# sam67_dmpac_wrap0_DMPAC_TOP_CFG_SLV_CP_INTD_CFG_INTD_CFG register map
Vendor: Texas Instruments
Registers are 32-bit, access not given, reset 0x0 unless marked. A register's access mark holds for its fields unless they carry their own. Offsets are as the file gives them; [hi:lo] are bit positions; {n}, {i} and the like mark numbered series.

## sam67_dmpac_wrap0_DMPAC_TOP_CFG_SLV_CP_INTD_CFG_INTD_CFG (part 2 of 2)
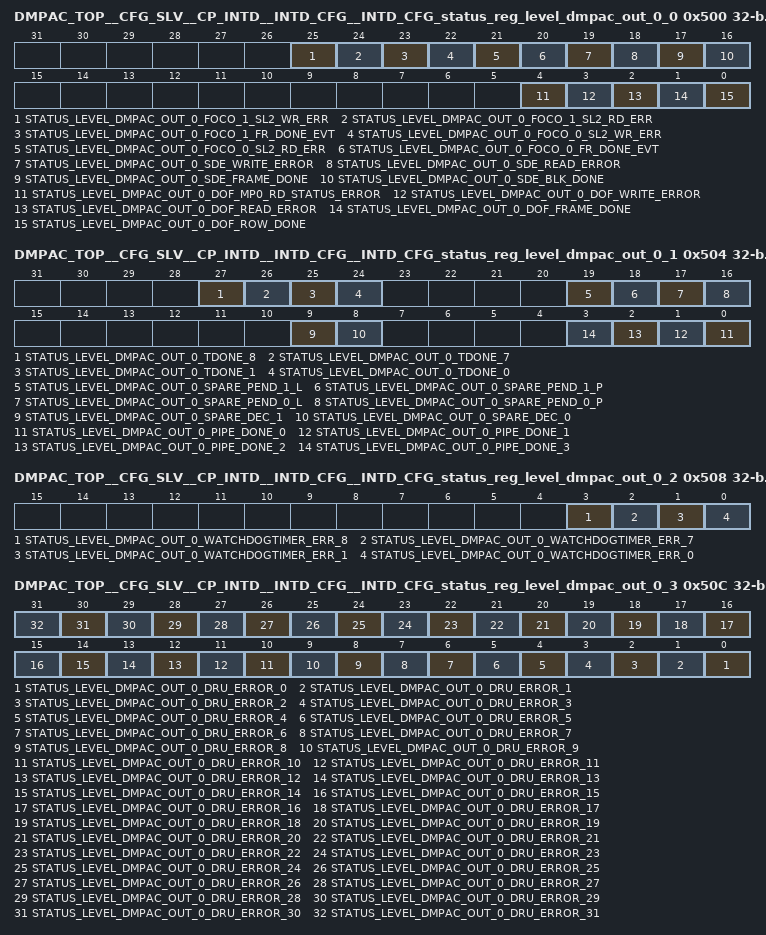
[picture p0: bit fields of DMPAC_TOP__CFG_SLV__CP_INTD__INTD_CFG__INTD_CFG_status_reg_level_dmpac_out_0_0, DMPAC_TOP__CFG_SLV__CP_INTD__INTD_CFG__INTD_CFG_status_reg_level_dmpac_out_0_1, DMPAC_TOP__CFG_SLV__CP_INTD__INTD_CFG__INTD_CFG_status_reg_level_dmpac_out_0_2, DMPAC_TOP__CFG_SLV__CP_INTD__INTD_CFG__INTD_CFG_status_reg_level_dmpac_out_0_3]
0x500 DMPAC_TOP__CFG_SLV__CP_INTD__INTD_CFG__INTD_CFG_status_reg_level_dmpac_out_0_0 — Status Register 0
  [25] STATUS_LEVEL_DMPAC_OUT_0_FOCO_1_SL2_WR_ERR — Status ,write 1 to set, for level_dmpac_out_0_en_foco_1_sl2_wr_err (access R/W1TS)
  [24] STATUS_LEVEL_DMPAC_OUT_0_FOCO_1_SL2_RD_ERR — Status ,write 1 to set, for level_dmpac_out_0_en_foco_1_sl2_rd_err (access R/W1TS)
  [23] STATUS_LEVEL_DMPAC_OUT_0_FOCO_1_FR_DONE_EVT — Status ,write 1 to set, for level_dmpac_out_0_en_foco_1_fr_done_evt (access R/W1TS)
  [22] STATUS_LEVEL_DMPAC_OUT_0_FOCO_0_SL2_WR_ERR — Status ,write 1 to set, for level_dmpac_out_0_en_foco_0_sl2_wr_err (access R/W1TS)
  [21] STATUS_LEVEL_DMPAC_OUT_0_FOCO_0_SL2_RD_ERR — Status ,write 1 to set, for level_dmpac_out_0_en_foco_0_sl2_rd_err (access R/W1TS)
  [20] STATUS_LEVEL_DMPAC_OUT_0_FOCO_0_FR_DONE_EVT — Status ,write 1 to set, for level_dmpac_out_0_en_foco_0_fr_done_evt (access R/W1TS)
  [19] STATUS_LEVEL_DMPAC_OUT_0_SDE_WRITE_ERROR — Status ,write 1 to set, for level_dmpac_out_0_en_sde_write_error (access R/W1TS)
  [18] STATUS_LEVEL_DMPAC_OUT_0_SDE_READ_ERROR — Status ,write 1 to set, for level_dmpac_out_0_en_sde_read_error (access R/W1TS)
  [17] STATUS_LEVEL_DMPAC_OUT_0_SDE_FRAME_DONE — Status ,write 1 to set, for level_dmpac_out_0_en_sde_frame_done (access R/W1TS)
  [16] STATUS_LEVEL_DMPAC_OUT_0_SDE_BLK_DONE — Status ,write 1 to set, for level_dmpac_out_0_en_sde_blk_done (access R/W1TS)
  [4] STATUS_LEVEL_DMPAC_OUT_0_DOF_MP0_RD_STATUS_ERROR — Status ,write 1 to set, for level_dmpac_out_0_en_dof_mp0_rd_status_error (access R/W1TS)
  [3] STATUS_LEVEL_DMPAC_OUT_0_DOF_WRITE_ERROR — Status ,write 1 to set, for level_dmpac_out_0_en_dof_write_error (access R/W1TS)
  [2] STATUS_LEVEL_DMPAC_OUT_0_DOF_READ_ERROR — Status ,write 1 to set, for level_dmpac_out_0_en_dof_read_error (access R/W1TS)
  [1] STATUS_LEVEL_DMPAC_OUT_0_DOF_FRAME_DONE — Status ,write 1 to set, for level_dmpac_out_0_en_dof_frame_done (access R/W1TS)
  [0] STATUS_LEVEL_DMPAC_OUT_0_DOF_ROW_DONE — Status ,write 1 to set, for level_dmpac_out_0_en_dof_row_done (access R/W1TS)
0x504 DMPAC_TOP__CFG_SLV__CP_INTD__INTD_CFG__INTD_CFG_status_reg_level_dmpac_out_0_1 — Status Register 1
  [27] STATUS_LEVEL_DMPAC_OUT_0_TDONE_8 — Status ,write 1 to set, for level_dmpac_out_0_en_tdone_8 (access R/W1TS)
  [26] STATUS_LEVEL_DMPAC_OUT_0_TDONE_7 — Status ,write 1 to set, for level_dmpac_out_0_en_tdone_7 (access R/W1TS)
  [25] STATUS_LEVEL_DMPAC_OUT_0_TDONE_1 — Status ,write 1 to set, for level_dmpac_out_0_en_tdone_1 (access R/W1TS)
  [24] STATUS_LEVEL_DMPAC_OUT_0_TDONE_0 — Status ,write 1 to set, for level_dmpac_out_0_en_tdone_0 (access R/W1TS)
  [19] STATUS_LEVEL_DMPAC_OUT_0_SPARE_PEND_1_L ro — Status for level_dmpac_out_0_en_spare_pend_1_l
  [18] STATUS_LEVEL_DMPAC_OUT_0_SPARE_PEND_1_P ro — Status for level_dmpac_out_0_en_spare_pend_1_p
  [17] STATUS_LEVEL_DMPAC_OUT_0_SPARE_PEND_0_L ro — Status for level_dmpac_out_0_en_spare_pend_0_l
  [16] STATUS_LEVEL_DMPAC_OUT_0_SPARE_PEND_0_P ro — Status for level_dmpac_out_0_en_spare_pend_0_p
  [9] STATUS_LEVEL_DMPAC_OUT_0_SPARE_DEC_1 — Status ,write 1 to set, for level_dmpac_out_0_en_spare_dec_1 (access R/W1TS)
  [8] STATUS_LEVEL_DMPAC_OUT_0_SPARE_DEC_0 — Status ,write 1 to set, for level_dmpac_out_0_en_spare_dec_0 (access R/W1TS)
  [n] STATUS_LEVEL_DMPAC_OUT_0_PIPE_DONE_{n} (n=0..3) — Status ,write 1 to set, for level_dmpac_out_0_en_pipe_done_{n} (access R/W1TS)
0x508 DMPAC_TOP__CFG_SLV__CP_INTD__INTD_CFG__INTD_CFG_status_reg_level_dmpac_out_0_2 — Status Register 2
  [3] STATUS_LEVEL_DMPAC_OUT_0_WATCHDOGTIMER_ERR_8 — Status ,write 1 to set, for level_dmpac_out_0_en_watchdogtimer_err_8 (access R/W1TS)
  [2] STATUS_LEVEL_DMPAC_OUT_0_WATCHDOGTIMER_ERR_7 — Status ,write 1 to set, for level_dmpac_out_0_en_watchdogtimer_err_7 (access R/W1TS)
  [1] STATUS_LEVEL_DMPAC_OUT_0_WATCHDOGTIMER_ERR_1 — Status ,write 1 to set, for level_dmpac_out_0_en_watchdogtimer_err_1 (access R/W1TS)
  [0] STATUS_LEVEL_DMPAC_OUT_0_WATCHDOGTIMER_ERR_0 — Status ,write 1 to set, for level_dmpac_out_0_en_watchdogtimer_err_0 (access R/W1TS)
0x50C DMPAC_TOP__CFG_SLV__CP_INTD__INTD_CFG__INTD_CFG_status_reg_level_dmpac_out_0_3 — Status Register 3
  [n] STATUS_LEVEL_DMPAC_OUT_0_DRU_ERROR_{n} (n=0..31) — Status ,write 1 to set, for level_dmpac_out_0_en_dru_error_{n} (access R/W1TS)
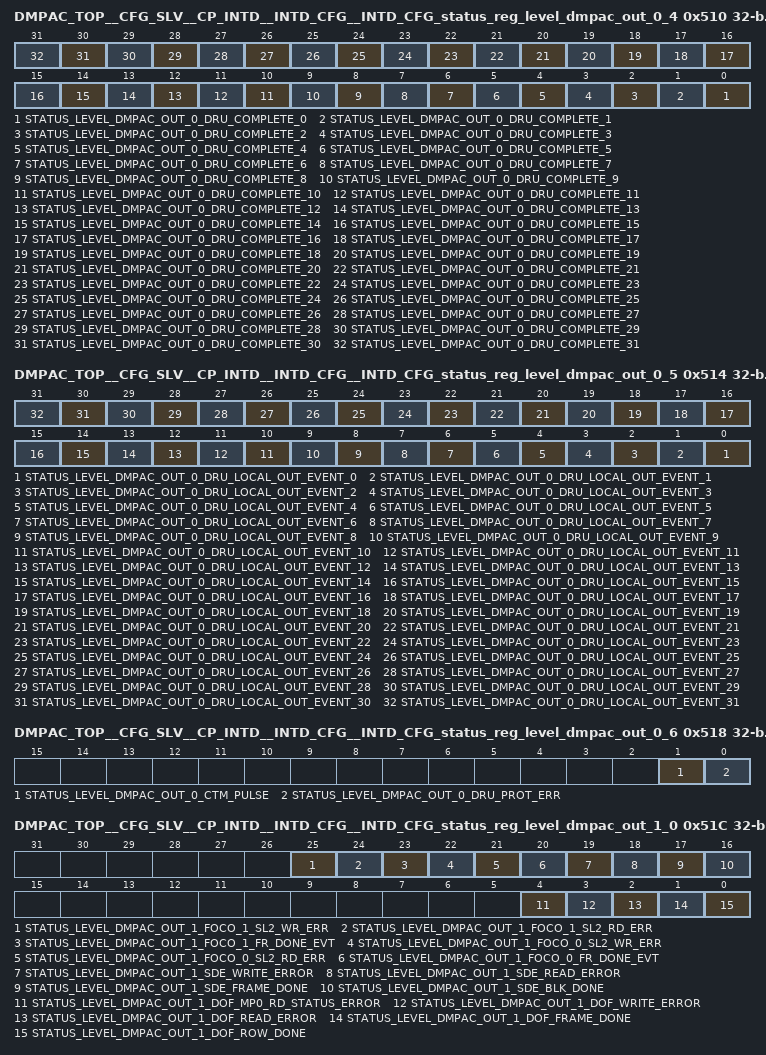
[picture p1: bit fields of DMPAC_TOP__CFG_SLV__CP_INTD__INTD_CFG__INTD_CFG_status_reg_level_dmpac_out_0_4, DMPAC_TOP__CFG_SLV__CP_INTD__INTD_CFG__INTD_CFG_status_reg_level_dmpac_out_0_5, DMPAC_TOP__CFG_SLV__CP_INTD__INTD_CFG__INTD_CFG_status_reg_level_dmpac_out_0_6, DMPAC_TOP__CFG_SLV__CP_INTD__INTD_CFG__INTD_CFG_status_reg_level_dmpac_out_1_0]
0x510 DMPAC_TOP__CFG_SLV__CP_INTD__INTD_CFG__INTD_CFG_status_reg_level_dmpac_out_0_4 — Status Register 4
  [n] STATUS_LEVEL_DMPAC_OUT_0_DRU_COMPLETE_{n} (n=0..31) — Status ,write 1 to set, for level_dmpac_out_0_en_dru_complete_{n} (access R/W1TS)
0x514 DMPAC_TOP__CFG_SLV__CP_INTD__INTD_CFG__INTD_CFG_status_reg_level_dmpac_out_0_5 — Status Register 5
  [n] STATUS_LEVEL_DMPAC_OUT_0_DRU_LOCAL_OUT_EVENT_{n} (n=0..31) — Status ,write 1 to set, for level_dmpac_out_0_en_dru_local_out_event_{n} (access R/W1TS)
0x518 DMPAC_TOP__CFG_SLV__CP_INTD__INTD_CFG__INTD_CFG_status_reg_level_dmpac_out_0_6 — Status Register 6
  [1] STATUS_LEVEL_DMPAC_OUT_0_CTM_PULSE — Status ,write 1 to set, for level_dmpac_out_0_en_ctm_pulse (access R/W1TS)
  [0] STATUS_LEVEL_DMPAC_OUT_0_DRU_PROT_ERR — Status ,write 1 to set, for level_dmpac_out_0_en_dru_prot_err (access R/W1TS)
0x51C DMPAC_TOP__CFG_SLV__CP_INTD__INTD_CFG__INTD_CFG_status_reg_level_dmpac_out_1_0 — Status Register 7
  [25] STATUS_LEVEL_DMPAC_OUT_1_FOCO_1_SL2_WR_ERR — Status ,write 1 to set, for level_dmpac_out_1_en_foco_1_sl2_wr_err (access R/W1TS)
  [24] STATUS_LEVEL_DMPAC_OUT_1_FOCO_1_SL2_RD_ERR — Status ,write 1 to set, for level_dmpac_out_1_en_foco_1_sl2_rd_err (access R/W1TS)
  [23] STATUS_LEVEL_DMPAC_OUT_1_FOCO_1_FR_DONE_EVT — Status ,write 1 to set, for level_dmpac_out_1_en_foco_1_fr_done_evt (access R/W1TS)
  [22] STATUS_LEVEL_DMPAC_OUT_1_FOCO_0_SL2_WR_ERR — Status ,write 1 to set, for level_dmpac_out_1_en_foco_0_sl2_wr_err (access R/W1TS)
  [21] STATUS_LEVEL_DMPAC_OUT_1_FOCO_0_SL2_RD_ERR — Status ,write 1 to set, for level_dmpac_out_1_en_foco_0_sl2_rd_err (access R/W1TS)
  [20] STATUS_LEVEL_DMPAC_OUT_1_FOCO_0_FR_DONE_EVT — Status ,write 1 to set, for level_dmpac_out_1_en_foco_0_fr_done_evt (access R/W1TS)
  [19] STATUS_LEVEL_DMPAC_OUT_1_SDE_WRITE_ERROR — Status ,write 1 to set, for level_dmpac_out_1_en_sde_write_error (access R/W1TS)
  [18] STATUS_LEVEL_DMPAC_OUT_1_SDE_READ_ERROR — Status ,write 1 to set, for level_dmpac_out_1_en_sde_read_error (access R/W1TS)
  [17] STATUS_LEVEL_DMPAC_OUT_1_SDE_FRAME_DONE — Status ,write 1 to set, for level_dmpac_out_1_en_sde_frame_done (access R/W1TS)
  [16] STATUS_LEVEL_DMPAC_OUT_1_SDE_BLK_DONE — Status ,write 1 to set, for level_dmpac_out_1_en_sde_blk_done (access R/W1TS)
  [4] STATUS_LEVEL_DMPAC_OUT_1_DOF_MP0_RD_STATUS_ERROR — Status ,write 1 to set, for level_dmpac_out_1_en_dof_mp0_rd_status_error (access R/W1TS)
  [3] STATUS_LEVEL_DMPAC_OUT_1_DOF_WRITE_ERROR — Status ,write 1 to set, for level_dmpac_out_1_en_dof_write_error (access R/W1TS)
  [2] STATUS_LEVEL_DMPAC_OUT_1_DOF_READ_ERROR — Status ,write 1 to set, for level_dmpac_out_1_en_dof_read_error (access R/W1TS)
  [1] STATUS_LEVEL_DMPAC_OUT_1_DOF_FRAME_DONE — Status ,write 1 to set, for level_dmpac_out_1_en_dof_frame_done (access R/W1TS)
  [0] STATUS_LEVEL_DMPAC_OUT_1_DOF_ROW_DONE — Status ,write 1 to set, for level_dmpac_out_1_en_dof_row_done (access R/W1TS)
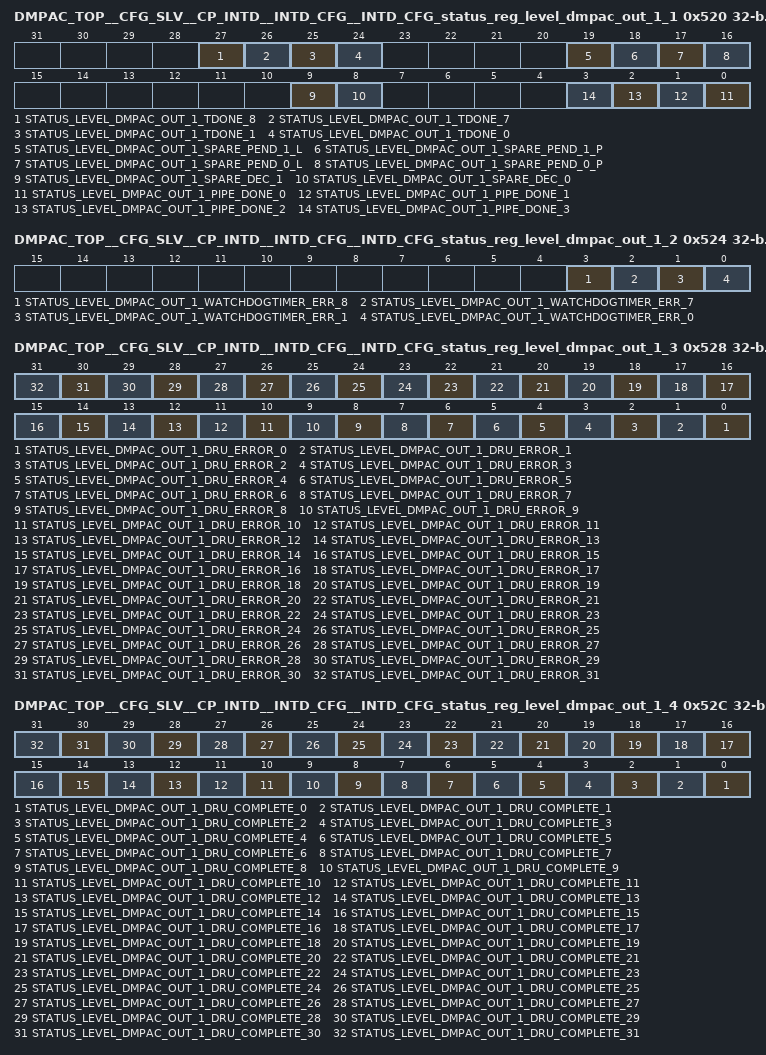
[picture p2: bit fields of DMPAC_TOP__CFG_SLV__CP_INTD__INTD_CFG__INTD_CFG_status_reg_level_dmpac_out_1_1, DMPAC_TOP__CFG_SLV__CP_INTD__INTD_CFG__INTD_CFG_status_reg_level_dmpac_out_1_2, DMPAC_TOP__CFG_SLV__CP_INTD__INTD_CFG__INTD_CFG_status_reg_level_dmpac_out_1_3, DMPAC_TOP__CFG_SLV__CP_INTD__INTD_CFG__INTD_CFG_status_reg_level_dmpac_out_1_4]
0x520 DMPAC_TOP__CFG_SLV__CP_INTD__INTD_CFG__INTD_CFG_status_reg_level_dmpac_out_1_1 — Status Register 8
  [27] STATUS_LEVEL_DMPAC_OUT_1_TDONE_8 — Status ,write 1 to set, for level_dmpac_out_1_en_tdone_8 (access R/W1TS)
  [26] STATUS_LEVEL_DMPAC_OUT_1_TDONE_7 — Status ,write 1 to set, for level_dmpac_out_1_en_tdone_7 (access R/W1TS)
  [25] STATUS_LEVEL_DMPAC_OUT_1_TDONE_1 — Status ,write 1 to set, for level_dmpac_out_1_en_tdone_1 (access R/W1TS)
  [24] STATUS_LEVEL_DMPAC_OUT_1_TDONE_0 — Status ,write 1 to set, for level_dmpac_out_1_en_tdone_0 (access R/W1TS)
  [19] STATUS_LEVEL_DMPAC_OUT_1_SPARE_PEND_1_L ro — Status for level_dmpac_out_1_en_spare_pend_1_l
  [18] STATUS_LEVEL_DMPAC_OUT_1_SPARE_PEND_1_P ro — Status for level_dmpac_out_1_en_spare_pend_1_p
  [17] STATUS_LEVEL_DMPAC_OUT_1_SPARE_PEND_0_L ro — Status for level_dmpac_out_1_en_spare_pend_0_l
  [16] STATUS_LEVEL_DMPAC_OUT_1_SPARE_PEND_0_P ro — Status for level_dmpac_out_1_en_spare_pend_0_p
  [9] STATUS_LEVEL_DMPAC_OUT_1_SPARE_DEC_1 — Status ,write 1 to set, for level_dmpac_out_1_en_spare_dec_1 (access R/W1TS)
  [8] STATUS_LEVEL_DMPAC_OUT_1_SPARE_DEC_0 — Status ,write 1 to set, for level_dmpac_out_1_en_spare_dec_0 (access R/W1TS)
  [n] STATUS_LEVEL_DMPAC_OUT_1_PIPE_DONE_{n} (n=0..3) — Status ,write 1 to set, for level_dmpac_out_1_en_pipe_done_{n} (access R/W1TS)
0x524 DMPAC_TOP__CFG_SLV__CP_INTD__INTD_CFG__INTD_CFG_status_reg_level_dmpac_out_1_2 — Status Register 9
  [3] STATUS_LEVEL_DMPAC_OUT_1_WATCHDOGTIMER_ERR_8 — Status ,write 1 to set, for level_dmpac_out_1_en_watchdogtimer_err_8 (access R/W1TS)
  [2] STATUS_LEVEL_DMPAC_OUT_1_WATCHDOGTIMER_ERR_7 — Status ,write 1 to set, for level_dmpac_out_1_en_watchdogtimer_err_7 (access R/W1TS)
  [1] STATUS_LEVEL_DMPAC_OUT_1_WATCHDOGTIMER_ERR_1 — Status ,write 1 to set, for level_dmpac_out_1_en_watchdogtimer_err_1 (access R/W1TS)
  [0] STATUS_LEVEL_DMPAC_OUT_1_WATCHDOGTIMER_ERR_0 — Status ,write 1 to set, for level_dmpac_out_1_en_watchdogtimer_err_0 (access R/W1TS)
0x528 DMPAC_TOP__CFG_SLV__CP_INTD__INTD_CFG__INTD_CFG_status_reg_level_dmpac_out_1_3 — Status Register 10
  [n] STATUS_LEVEL_DMPAC_OUT_1_DRU_ERROR_{n} (n=0..31) — Status ,write 1 to set, for level_dmpac_out_1_en_dru_error_{n} (access R/W1TS)
0x52C DMPAC_TOP__CFG_SLV__CP_INTD__INTD_CFG__INTD_CFG_status_reg_level_dmpac_out_1_4 — Status Register 11
  [n] STATUS_LEVEL_DMPAC_OUT_1_DRU_COMPLETE_{n} (n=0..31) — Status ,write 1 to set, for level_dmpac_out_1_en_dru_complete_{n} (access R/W1TS)
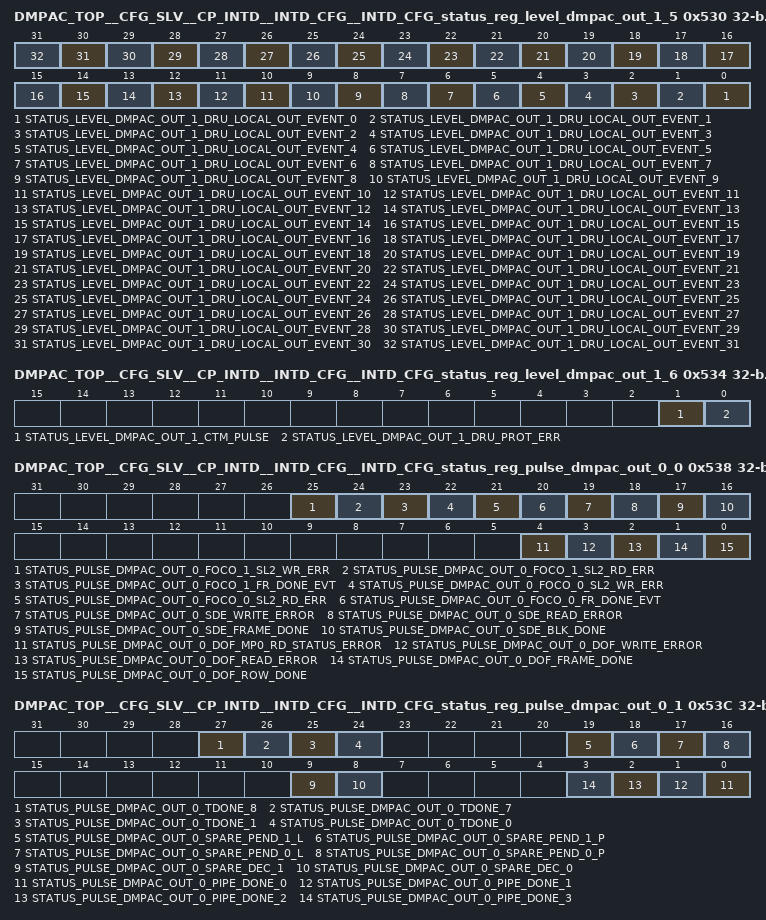
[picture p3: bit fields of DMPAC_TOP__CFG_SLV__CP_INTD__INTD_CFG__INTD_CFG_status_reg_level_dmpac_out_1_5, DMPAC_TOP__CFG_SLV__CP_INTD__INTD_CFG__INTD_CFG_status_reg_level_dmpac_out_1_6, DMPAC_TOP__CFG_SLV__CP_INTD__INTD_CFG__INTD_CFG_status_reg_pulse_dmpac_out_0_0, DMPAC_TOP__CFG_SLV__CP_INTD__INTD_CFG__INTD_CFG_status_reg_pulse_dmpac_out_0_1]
0x530 DMPAC_TOP__CFG_SLV__CP_INTD__INTD_CFG__INTD_CFG_status_reg_level_dmpac_out_1_5 — Status Register 12
  [n] STATUS_LEVEL_DMPAC_OUT_1_DRU_LOCAL_OUT_EVENT_{n} (n=0..31) — Status ,write 1 to set, for level_dmpac_out_1_en_dru_local_out_event_{n} (access R/W1TS)
0x534 DMPAC_TOP__CFG_SLV__CP_INTD__INTD_CFG__INTD_CFG_status_reg_level_dmpac_out_1_6 — Status Register 13
  [1] STATUS_LEVEL_DMPAC_OUT_1_CTM_PULSE — Status ,write 1 to set, for level_dmpac_out_1_en_ctm_pulse (access R/W1TS)
  [0] STATUS_LEVEL_DMPAC_OUT_1_DRU_PROT_ERR — Status ,write 1 to set, for level_dmpac_out_1_en_dru_prot_err (access R/W1TS)
0x538 DMPAC_TOP__CFG_SLV__CP_INTD__INTD_CFG__INTD_CFG_status_reg_pulse_dmpac_out_0_0 — Status Register 14
  [25] STATUS_PULSE_DMPAC_OUT_0_FOCO_1_SL2_WR_ERR — Status ,write 1 to set, for pulse_dmpac_out_0_en_foco_1_sl2_wr_err (access R/W1TS)
  [24] STATUS_PULSE_DMPAC_OUT_0_FOCO_1_SL2_RD_ERR — Status ,write 1 to set, for pulse_dmpac_out_0_en_foco_1_sl2_rd_err (access R/W1TS)
  [23] STATUS_PULSE_DMPAC_OUT_0_FOCO_1_FR_DONE_EVT — Status ,write 1 to set, for pulse_dmpac_out_0_en_foco_1_fr_done_evt (access R/W1TS)
  [22] STATUS_PULSE_DMPAC_OUT_0_FOCO_0_SL2_WR_ERR — Status ,write 1 to set, for pulse_dmpac_out_0_en_foco_0_sl2_wr_err (access R/W1TS)
  [21] STATUS_PULSE_DMPAC_OUT_0_FOCO_0_SL2_RD_ERR — Status ,write 1 to set, for pulse_dmpac_out_0_en_foco_0_sl2_rd_err (access R/W1TS)
  [20] STATUS_PULSE_DMPAC_OUT_0_FOCO_0_FR_DONE_EVT — Status ,write 1 to set, for pulse_dmpac_out_0_en_foco_0_fr_done_evt (access R/W1TS)
  [19] STATUS_PULSE_DMPAC_OUT_0_SDE_WRITE_ERROR — Status ,write 1 to set, for pulse_dmpac_out_0_en_sde_write_error (access R/W1TS)
  [18] STATUS_PULSE_DMPAC_OUT_0_SDE_READ_ERROR — Status ,write 1 to set, for pulse_dmpac_out_0_en_sde_read_error (access R/W1TS)
  [17] STATUS_PULSE_DMPAC_OUT_0_SDE_FRAME_DONE — Status ,write 1 to set, for pulse_dmpac_out_0_en_sde_frame_done (access R/W1TS)
  [16] STATUS_PULSE_DMPAC_OUT_0_SDE_BLK_DONE — Status ,write 1 to set, for pulse_dmpac_out_0_en_sde_blk_done (access R/W1TS)
  [4] STATUS_PULSE_DMPAC_OUT_0_DOF_MP0_RD_STATUS_ERROR — Status ,write 1 to set, for pulse_dmpac_out_0_en_dof_mp0_rd_status_error (access R/W1TS)
  [3] STATUS_PULSE_DMPAC_OUT_0_DOF_WRITE_ERROR — Status ,write 1 to set, for pulse_dmpac_out_0_en_dof_write_error (access R/W1TS)
  [2] STATUS_PULSE_DMPAC_OUT_0_DOF_READ_ERROR — Status ,write 1 to set, for pulse_dmpac_out_0_en_dof_read_error (access R/W1TS)
  [1] STATUS_PULSE_DMPAC_OUT_0_DOF_FRAME_DONE — Status ,write 1 to set, for pulse_dmpac_out_0_en_dof_frame_done (access R/W1TS)
  [0] STATUS_PULSE_DMPAC_OUT_0_DOF_ROW_DONE — Status ,write 1 to set, for pulse_dmpac_out_0_en_dof_row_done (access R/W1TS)
0x53C DMPAC_TOP__CFG_SLV__CP_INTD__INTD_CFG__INTD_CFG_status_reg_pulse_dmpac_out_0_1 — Status Register 15
  [27] STATUS_PULSE_DMPAC_OUT_0_TDONE_8 — Status ,write 1 to set, for pulse_dmpac_out_0_en_tdone_8 (access R/W1TS)
  [26] STATUS_PULSE_DMPAC_OUT_0_TDONE_7 — Status ,write 1 to set, for pulse_dmpac_out_0_en_tdone_7 (access R/W1TS)
  [25] STATUS_PULSE_DMPAC_OUT_0_TDONE_1 — Status ,write 1 to set, for pulse_dmpac_out_0_en_tdone_1 (access R/W1TS)
  [24] STATUS_PULSE_DMPAC_OUT_0_TDONE_0 — Status ,write 1 to set, for pulse_dmpac_out_0_en_tdone_0 (access R/W1TS)
  [19] STATUS_PULSE_DMPAC_OUT_0_SPARE_PEND_1_L ro — Status for pulse_dmpac_out_0_en_spare_pend_1_l
  [18] STATUS_PULSE_DMPAC_OUT_0_SPARE_PEND_1_P ro — Status for pulse_dmpac_out_0_en_spare_pend_1_p
  [17] STATUS_PULSE_DMPAC_OUT_0_SPARE_PEND_0_L ro — Status for pulse_dmpac_out_0_en_spare_pend_0_l
  [16] STATUS_PULSE_DMPAC_OUT_0_SPARE_PEND_0_P ro — Status for pulse_dmpac_out_0_en_spare_pend_0_p
  [9] STATUS_PULSE_DMPAC_OUT_0_SPARE_DEC_1 — Status ,write 1 to set, for pulse_dmpac_out_0_en_spare_dec_1 (access R/W1TS)
  [8] STATUS_PULSE_DMPAC_OUT_0_SPARE_DEC_0 — Status ,write 1 to set, for pulse_dmpac_out_0_en_spare_dec_0 (access R/W1TS)
  [n] STATUS_PULSE_DMPAC_OUT_0_PIPE_DONE_{n} (n=0..3) — Status ,write 1 to set, for pulse_dmpac_out_0_en_pipe_done_{n} (access R/W1TS)
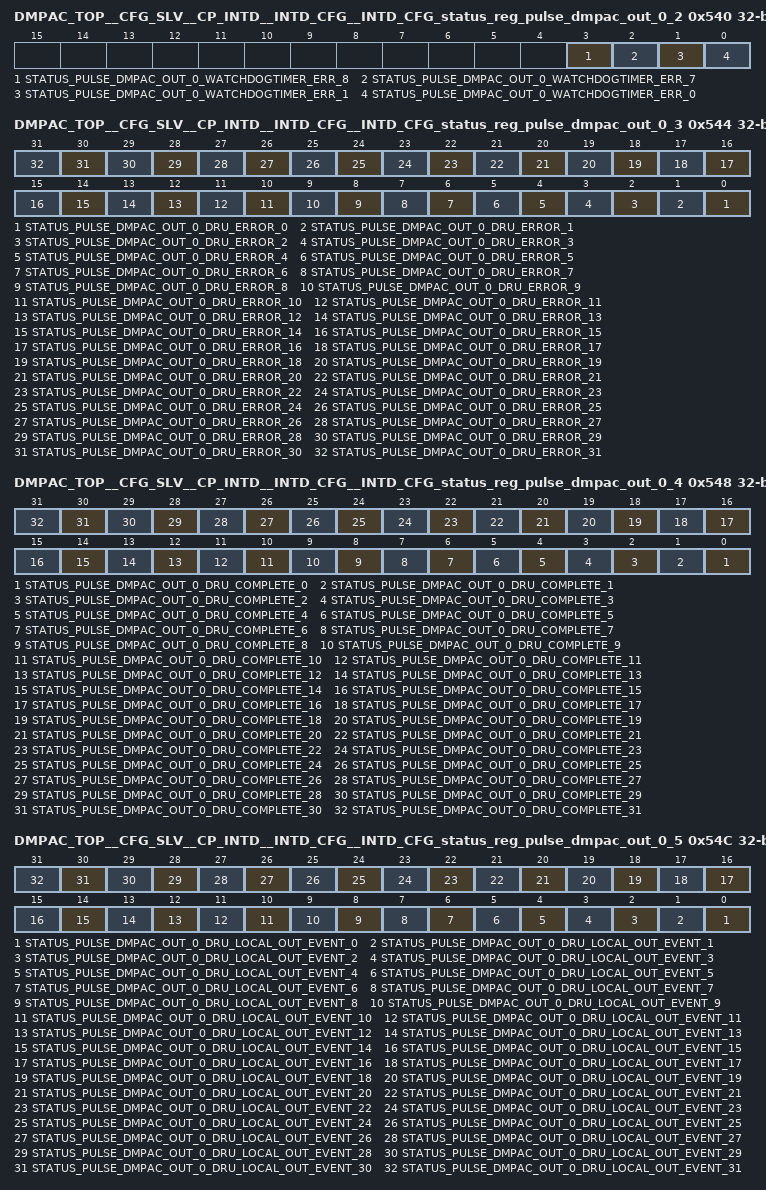
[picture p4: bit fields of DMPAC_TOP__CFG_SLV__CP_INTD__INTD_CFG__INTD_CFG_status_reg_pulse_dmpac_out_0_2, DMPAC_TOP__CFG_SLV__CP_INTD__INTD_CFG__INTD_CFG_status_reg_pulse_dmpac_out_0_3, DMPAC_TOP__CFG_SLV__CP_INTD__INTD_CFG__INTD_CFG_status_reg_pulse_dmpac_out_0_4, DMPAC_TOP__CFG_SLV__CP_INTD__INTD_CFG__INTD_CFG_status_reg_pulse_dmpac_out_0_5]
0x540 DMPAC_TOP__CFG_SLV__CP_INTD__INTD_CFG__INTD_CFG_status_reg_pulse_dmpac_out_0_2 — Status Register 16
  [3] STATUS_PULSE_DMPAC_OUT_0_WATCHDOGTIMER_ERR_8 — Status ,write 1 to set, for pulse_dmpac_out_0_en_watchdogtimer_err_8 (access R/W1TS)
  [2] STATUS_PULSE_DMPAC_OUT_0_WATCHDOGTIMER_ERR_7 — Status ,write 1 to set, for pulse_dmpac_out_0_en_watchdogtimer_err_7 (access R/W1TS)
  [1] STATUS_PULSE_DMPAC_OUT_0_WATCHDOGTIMER_ERR_1 — Status ,write 1 to set, for pulse_dmpac_out_0_en_watchdogtimer_err_1 (access R/W1TS)
  [0] STATUS_PULSE_DMPAC_OUT_0_WATCHDOGTIMER_ERR_0 — Status ,write 1 to set, for pulse_dmpac_out_0_en_watchdogtimer_err_0 (access R/W1TS)
0x544 DMPAC_TOP__CFG_SLV__CP_INTD__INTD_CFG__INTD_CFG_status_reg_pulse_dmpac_out_0_3 — Status Register 17
  [n] STATUS_PULSE_DMPAC_OUT_0_DRU_ERROR_{n} (n=0..31) — Status ,write 1 to set, for pulse_dmpac_out_0_en_dru_error_{n} (access R/W1TS)
0x548 DMPAC_TOP__CFG_SLV__CP_INTD__INTD_CFG__INTD_CFG_status_reg_pulse_dmpac_out_0_4 — Status Register 18
  [n] STATUS_PULSE_DMPAC_OUT_0_DRU_COMPLETE_{n} (n=0..31) — Status ,write 1 to set, for pulse_dmpac_out_0_en_dru_complete_{n} (access R/W1TS)
0x54C DMPAC_TOP__CFG_SLV__CP_INTD__INTD_CFG__INTD_CFG_status_reg_pulse_dmpac_out_0_5 — Status Register 19
  [n] STATUS_PULSE_DMPAC_OUT_0_DRU_LOCAL_OUT_EVENT_{n} (n=0..31) — Status ,write 1 to set, for pulse_dmpac_out_0_en_dru_local_out_event_{n} (access R/W1TS)
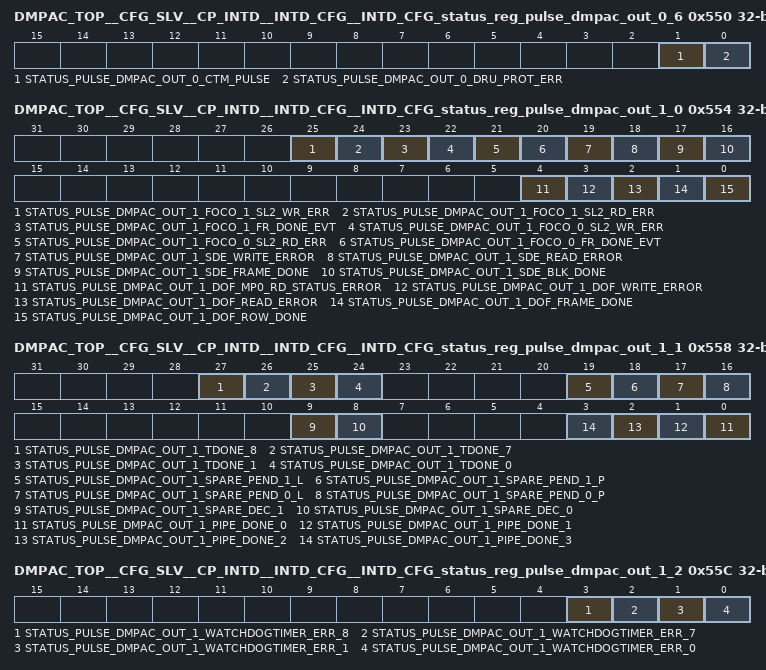
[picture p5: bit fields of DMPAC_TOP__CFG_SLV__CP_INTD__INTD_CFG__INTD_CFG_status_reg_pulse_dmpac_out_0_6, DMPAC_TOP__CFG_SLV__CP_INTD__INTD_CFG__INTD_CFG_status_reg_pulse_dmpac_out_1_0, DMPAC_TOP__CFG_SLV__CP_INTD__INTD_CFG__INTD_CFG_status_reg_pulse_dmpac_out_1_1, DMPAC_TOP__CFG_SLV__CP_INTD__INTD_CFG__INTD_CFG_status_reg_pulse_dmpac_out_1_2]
0x550 DMPAC_TOP__CFG_SLV__CP_INTD__INTD_CFG__INTD_CFG_status_reg_pulse_dmpac_out_0_6 — Status Register 20
  [1] STATUS_PULSE_DMPAC_OUT_0_CTM_PULSE — Status ,write 1 to set, for pulse_dmpac_out_0_en_ctm_pulse (access R/W1TS)
  [0] STATUS_PULSE_DMPAC_OUT_0_DRU_PROT_ERR — Status ,write 1 to set, for pulse_dmpac_out_0_en_dru_prot_err (access R/W1TS)
0x554 DMPAC_TOP__CFG_SLV__CP_INTD__INTD_CFG__INTD_CFG_status_reg_pulse_dmpac_out_1_0 — Status Register 21
  [25] STATUS_PULSE_DMPAC_OUT_1_FOCO_1_SL2_WR_ERR — Status ,write 1 to set, for pulse_dmpac_out_1_en_foco_1_sl2_wr_err (access R/W1TS)
  [24] STATUS_PULSE_DMPAC_OUT_1_FOCO_1_SL2_RD_ERR — Status ,write 1 to set, for pulse_dmpac_out_1_en_foco_1_sl2_rd_err (access R/W1TS)
  [23] STATUS_PULSE_DMPAC_OUT_1_FOCO_1_FR_DONE_EVT — Status ,write 1 to set, for pulse_dmpac_out_1_en_foco_1_fr_done_evt (access R/W1TS)
  [22] STATUS_PULSE_DMPAC_OUT_1_FOCO_0_SL2_WR_ERR — Status ,write 1 to set, for pulse_dmpac_out_1_en_foco_0_sl2_wr_err (access R/W1TS)
  [21] STATUS_PULSE_DMPAC_OUT_1_FOCO_0_SL2_RD_ERR — Status ,write 1 to set, for pulse_dmpac_out_1_en_foco_0_sl2_rd_err (access R/W1TS)
  [20] STATUS_PULSE_DMPAC_OUT_1_FOCO_0_FR_DONE_EVT — Status ,write 1 to set, for pulse_dmpac_out_1_en_foco_0_fr_done_evt (access R/W1TS)
  [19] STATUS_PULSE_DMPAC_OUT_1_SDE_WRITE_ERROR — Status ,write 1 to set, for pulse_dmpac_out_1_en_sde_write_error (access R/W1TS)
  [18] STATUS_PULSE_DMPAC_OUT_1_SDE_READ_ERROR — Status ,write 1 to set, for pulse_dmpac_out_1_en_sde_read_error (access R/W1TS)
  [17] STATUS_PULSE_DMPAC_OUT_1_SDE_FRAME_DONE — Status ,write 1 to set, for pulse_dmpac_out_1_en_sde_frame_done (access R/W1TS)
  [16] STATUS_PULSE_DMPAC_OUT_1_SDE_BLK_DONE — Status ,write 1 to set, for pulse_dmpac_out_1_en_sde_blk_done (access R/W1TS)
  [4] STATUS_PULSE_DMPAC_OUT_1_DOF_MP0_RD_STATUS_ERROR — Status ,write 1 to set, for pulse_dmpac_out_1_en_dof_mp0_rd_status_error (access R/W1TS)
  [3] STATUS_PULSE_DMPAC_OUT_1_DOF_WRITE_ERROR — Status ,write 1 to set, for pulse_dmpac_out_1_en_dof_write_error (access R/W1TS)
  [2] STATUS_PULSE_DMPAC_OUT_1_DOF_READ_ERROR — Status ,write 1 to set, for pulse_dmpac_out_1_en_dof_read_error (access R/W1TS)
  [1] STATUS_PULSE_DMPAC_OUT_1_DOF_FRAME_DONE — Status ,write 1 to set, for pulse_dmpac_out_1_en_dof_frame_done (access R/W1TS)
  [0] STATUS_PULSE_DMPAC_OUT_1_DOF_ROW_DONE — Status ,write 1 to set, for pulse_dmpac_out_1_en_dof_row_done (access R/W1TS)
0x558 DMPAC_TOP__CFG_SLV__CP_INTD__INTD_CFG__INTD_CFG_status_reg_pulse_dmpac_out_1_1 — Status Register 22
  [27] STATUS_PULSE_DMPAC_OUT_1_TDONE_8 — Status ,write 1 to set, for pulse_dmpac_out_1_en_tdone_8 (access R/W1TS)
  [26] STATUS_PULSE_DMPAC_OUT_1_TDONE_7 — Status ,write 1 to set, for pulse_dmpac_out_1_en_tdone_7 (access R/W1TS)
  [25] STATUS_PULSE_DMPAC_OUT_1_TDONE_1 — Status ,write 1 to set, for pulse_dmpac_out_1_en_tdone_1 (access R/W1TS)
  [24] STATUS_PULSE_DMPAC_OUT_1_TDONE_0 — Status ,write 1 to set, for pulse_dmpac_out_1_en_tdone_0 (access R/W1TS)
  [19] STATUS_PULSE_DMPAC_OUT_1_SPARE_PEND_1_L ro — Status for pulse_dmpac_out_1_en_spare_pend_1_l
  [18] STATUS_PULSE_DMPAC_OUT_1_SPARE_PEND_1_P ro — Status for pulse_dmpac_out_1_en_spare_pend_1_p
  [17] STATUS_PULSE_DMPAC_OUT_1_SPARE_PEND_0_L ro — Status for pulse_dmpac_out_1_en_spare_pend_0_l
  [16] STATUS_PULSE_DMPAC_OUT_1_SPARE_PEND_0_P ro — Status for pulse_dmpac_out_1_en_spare_pend_0_p
  [9] STATUS_PULSE_DMPAC_OUT_1_SPARE_DEC_1 — Status ,write 1 to set, for pulse_dmpac_out_1_en_spare_dec_1 (access R/W1TS)
  [8] STATUS_PULSE_DMPAC_OUT_1_SPARE_DEC_0 — Status ,write 1 to set, for pulse_dmpac_out_1_en_spare_dec_0 (access R/W1TS)
  [n] STATUS_PULSE_DMPAC_OUT_1_PIPE_DONE_{n} (n=0..3) — Status ,write 1 to set, for pulse_dmpac_out_1_en_pipe_done_{n} (access R/W1TS)
0x55C DMPAC_TOP__CFG_SLV__CP_INTD__INTD_CFG__INTD_CFG_status_reg_pulse_dmpac_out_1_2 — Status Register 23
  [3] STATUS_PULSE_DMPAC_OUT_1_WATCHDOGTIMER_ERR_8 — Status ,write 1 to set, for pulse_dmpac_out_1_en_watchdogtimer_err_8 (access R/W1TS)
  [2] STATUS_PULSE_DMPAC_OUT_1_WATCHDOGTIMER_ERR_7 — Status ,write 1 to set, for pulse_dmpac_out_1_en_watchdogtimer_err_7 (access R/W1TS)
  [1] STATUS_PULSE_DMPAC_OUT_1_WATCHDOGTIMER_ERR_1 — Status ,write 1 to set, for pulse_dmpac_out_1_en_watchdogtimer_err_1 (access R/W1TS)
  [0] STATUS_PULSE_DMPAC_OUT_1_WATCHDOGTIMER_ERR_0 — Status ,write 1 to set, for pulse_dmpac_out_1_en_watchdogtimer_err_0 (access R/W1TS)
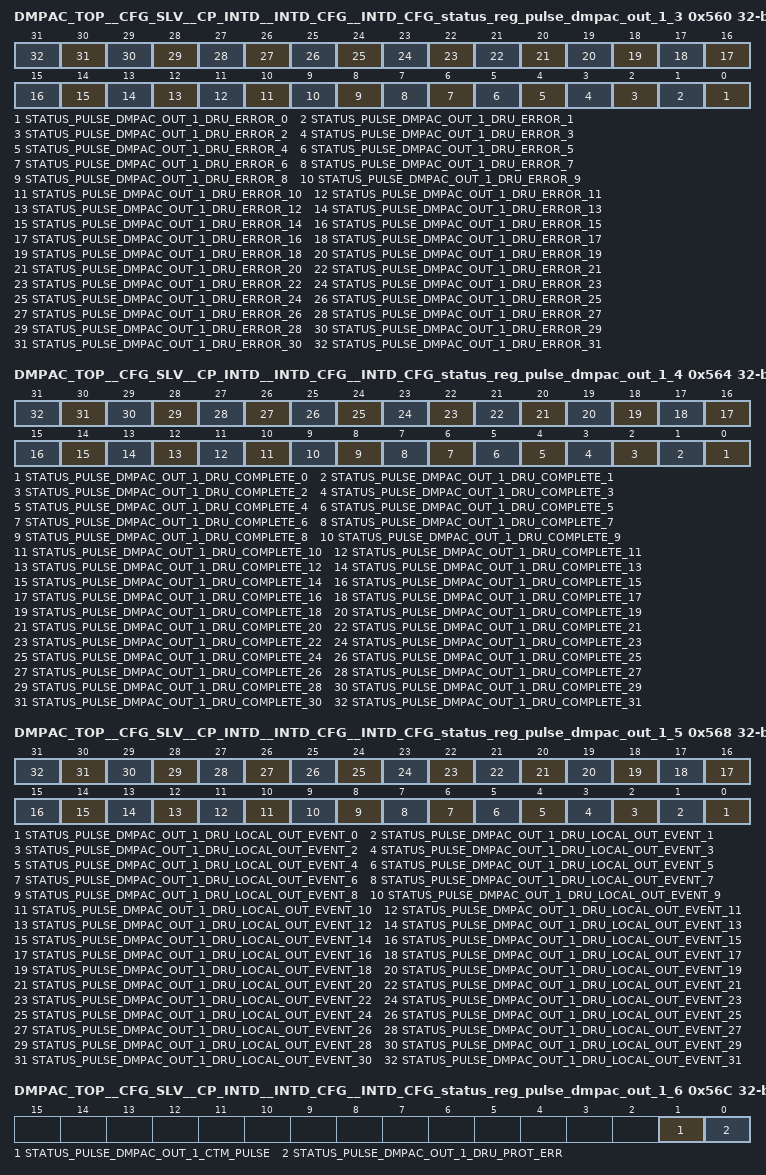
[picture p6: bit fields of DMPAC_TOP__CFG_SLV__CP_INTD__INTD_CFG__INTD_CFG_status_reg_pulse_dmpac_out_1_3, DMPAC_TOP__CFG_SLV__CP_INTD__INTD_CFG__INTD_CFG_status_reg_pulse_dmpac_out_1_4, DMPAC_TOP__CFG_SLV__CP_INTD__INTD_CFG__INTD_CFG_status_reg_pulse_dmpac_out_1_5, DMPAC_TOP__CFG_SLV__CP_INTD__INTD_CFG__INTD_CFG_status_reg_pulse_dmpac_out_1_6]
0x560 DMPAC_TOP__CFG_SLV__CP_INTD__INTD_CFG__INTD_CFG_status_reg_pulse_dmpac_out_1_3 — Status Register 24
  [n] STATUS_PULSE_DMPAC_OUT_1_DRU_ERROR_{n} (n=0..31) — Status ,write 1 to set, for pulse_dmpac_out_1_en_dru_error_{n} (access R/W1TS)
0x564 DMPAC_TOP__CFG_SLV__CP_INTD__INTD_CFG__INTD_CFG_status_reg_pulse_dmpac_out_1_4 — Status Register 25
  [n] STATUS_PULSE_DMPAC_OUT_1_DRU_COMPLETE_{n} (n=0..31) — Status ,write 1 to set, for pulse_dmpac_out_1_en_dru_complete_{n} (access R/W1TS)
0x568 DMPAC_TOP__CFG_SLV__CP_INTD__INTD_CFG__INTD_CFG_status_reg_pulse_dmpac_out_1_5 — Status Register 26
  [n] STATUS_PULSE_DMPAC_OUT_1_DRU_LOCAL_OUT_EVENT_{n} (n=0..31) — Status ,write 1 to set, for pulse_dmpac_out_1_en_dru_local_out_event_{n} (access R/W1TS)
0x56C DMPAC_TOP__CFG_SLV__CP_INTD__INTD_CFG__INTD_CFG_status_reg_pulse_dmpac_out_1_6 — Status Register 27
  [1] STATUS_PULSE_DMPAC_OUT_1_CTM_PULSE — Status ,write 1 to set, for pulse_dmpac_out_1_en_ctm_pulse (access R/W1TS)
  [0] STATUS_PULSE_DMPAC_OUT_1_DRU_PROT_ERR — Status ,write 1 to set, for pulse_dmpac_out_1_en_dru_prot_err (access R/W1TS)
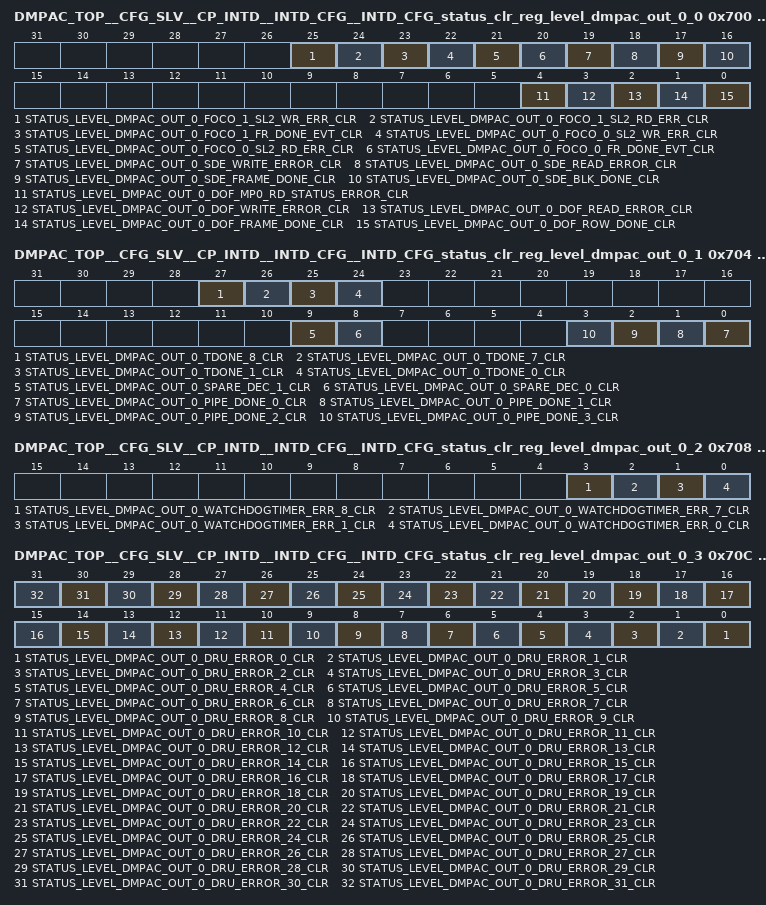
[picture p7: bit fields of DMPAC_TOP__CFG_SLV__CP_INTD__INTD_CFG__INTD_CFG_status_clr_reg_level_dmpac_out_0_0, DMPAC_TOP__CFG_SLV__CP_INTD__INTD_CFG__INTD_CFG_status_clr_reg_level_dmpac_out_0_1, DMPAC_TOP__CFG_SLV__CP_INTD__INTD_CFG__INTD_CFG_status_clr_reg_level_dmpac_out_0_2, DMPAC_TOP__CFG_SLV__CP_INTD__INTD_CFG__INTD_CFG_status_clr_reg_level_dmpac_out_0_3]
0x700 DMPAC_TOP__CFG_SLV__CP_INTD__INTD_CFG__INTD_CFG_status_clr_reg_level_dmpac_out_0_0 — Status Clear Register 0
  [25] STATUS_LEVEL_DMPAC_OUT_0_FOCO_1_SL2_WR_ERR_CLR — Status ,write 1 to clear, for level_dmpac_out_0_en_foco_1_sl2_wr_err (access R/W1TC)
  [24] STATUS_LEVEL_DMPAC_OUT_0_FOCO_1_SL2_RD_ERR_CLR — Status ,write 1 to clear, for level_dmpac_out_0_en_foco_1_sl2_rd_err (access R/W1TC)
  [23] STATUS_LEVEL_DMPAC_OUT_0_FOCO_1_FR_DONE_EVT_CLR — Status ,write 1 to clear, for level_dmpac_out_0_en_foco_1_fr_done_evt (access R/W1TC)
  [22] STATUS_LEVEL_DMPAC_OUT_0_FOCO_0_SL2_WR_ERR_CLR — Status ,write 1 to clear, for level_dmpac_out_0_en_foco_0_sl2_wr_err (access R/W1TC)
  [21] STATUS_LEVEL_DMPAC_OUT_0_FOCO_0_SL2_RD_ERR_CLR — Status ,write 1 to clear, for level_dmpac_out_0_en_foco_0_sl2_rd_err (access R/W1TC)
  [20] STATUS_LEVEL_DMPAC_OUT_0_FOCO_0_FR_DONE_EVT_CLR — Status ,write 1 to clear, for level_dmpac_out_0_en_foco_0_fr_done_evt (access R/W1TC)
  [19] STATUS_LEVEL_DMPAC_OUT_0_SDE_WRITE_ERROR_CLR — Status ,write 1 to clear, for level_dmpac_out_0_en_sde_write_error (access R/W1TC)
  [18] STATUS_LEVEL_DMPAC_OUT_0_SDE_READ_ERROR_CLR — Status ,write 1 to clear, for level_dmpac_out_0_en_sde_read_error (access R/W1TC)
  [17] STATUS_LEVEL_DMPAC_OUT_0_SDE_FRAME_DONE_CLR — Status ,write 1 to clear, for level_dmpac_out_0_en_sde_frame_done (access R/W1TC)
  [16] STATUS_LEVEL_DMPAC_OUT_0_SDE_BLK_DONE_CLR — Status ,write 1 to clear, for level_dmpac_out_0_en_sde_blk_done (access R/W1TC)
  [4] STATUS_LEVEL_DMPAC_OUT_0_DOF_MP0_RD_STATUS_ERROR_CLR — Status ,write 1 to clear, for level_dmpac_out_0_en_dof_mp0_rd_status_error (access R/W1TC)
  [3] STATUS_LEVEL_DMPAC_OUT_0_DOF_WRITE_ERROR_CLR — Status ,write 1 to clear, for level_dmpac_out_0_en_dof_write_error (access R/W1TC)
  [2] STATUS_LEVEL_DMPAC_OUT_0_DOF_READ_ERROR_CLR — Status ,write 1 to clear, for level_dmpac_out_0_en_dof_read_error (access R/W1TC)
  [1] STATUS_LEVEL_DMPAC_OUT_0_DOF_FRAME_DONE_CLR — Status ,write 1 to clear, for level_dmpac_out_0_en_dof_frame_done (access R/W1TC)
  [0] STATUS_LEVEL_DMPAC_OUT_0_DOF_ROW_DONE_CLR — Status ,write 1 to clear, for level_dmpac_out_0_en_dof_row_done (access R/W1TC)
0x704 DMPAC_TOP__CFG_SLV__CP_INTD__INTD_CFG__INTD_CFG_status_clr_reg_level_dmpac_out_0_1 — Status Clear Register 1
  [27] STATUS_LEVEL_DMPAC_OUT_0_TDONE_8_CLR — Status ,write 1 to clear, for level_dmpac_out_0_en_tdone_8 (access R/W1TC)
  [26] STATUS_LEVEL_DMPAC_OUT_0_TDONE_7_CLR — Status ,write 1 to clear, for level_dmpac_out_0_en_tdone_7 (access R/W1TC)
  [25] STATUS_LEVEL_DMPAC_OUT_0_TDONE_1_CLR — Status ,write 1 to clear, for level_dmpac_out_0_en_tdone_1 (access R/W1TC)
  [24] STATUS_LEVEL_DMPAC_OUT_0_TDONE_0_CLR — Status ,write 1 to clear, for level_dmpac_out_0_en_tdone_0 (access R/W1TC)
  [9] STATUS_LEVEL_DMPAC_OUT_0_SPARE_DEC_1_CLR — Status ,write 1 to clear, for level_dmpac_out_0_en_spare_dec_1 (access R/W1TC)
  [8] STATUS_LEVEL_DMPAC_OUT_0_SPARE_DEC_0_CLR — Status ,write 1 to clear, for level_dmpac_out_0_en_spare_dec_0 (access R/W1TC)
  [n] STATUS_LEVEL_DMPAC_OUT_0_PIPE_DONE_{n}_CLR (n=0..3) — Status ,write 1 to clear, for level_dmpac_out_0_en_pipe_done_{n} (access R/W1TC)
0x708 DMPAC_TOP__CFG_SLV__CP_INTD__INTD_CFG__INTD_CFG_status_clr_reg_level_dmpac_out_0_2 — Status Clear Register 2
  [3] STATUS_LEVEL_DMPAC_OUT_0_WATCHDOGTIMER_ERR_8_CLR — Status ,write 1 to clear, for level_dmpac_out_0_en_watchdogtimer_err_8 (access R/W1TC)
  [2] STATUS_LEVEL_DMPAC_OUT_0_WATCHDOGTIMER_ERR_7_CLR — Status ,write 1 to clear, for level_dmpac_out_0_en_watchdogtimer_err_7 (access R/W1TC)
  [1] STATUS_LEVEL_DMPAC_OUT_0_WATCHDOGTIMER_ERR_1_CLR — Status ,write 1 to clear, for level_dmpac_out_0_en_watchdogtimer_err_1 (access R/W1TC)
  [0] STATUS_LEVEL_DMPAC_OUT_0_WATCHDOGTIMER_ERR_0_CLR — Status ,write 1 to clear, for level_dmpac_out_0_en_watchdogtimer_err_0 (access R/W1TC)
0x70C DMPAC_TOP__CFG_SLV__CP_INTD__INTD_CFG__INTD_CFG_status_clr_reg_level_dmpac_out_0_3 — Status Clear Register 3
  [n] STATUS_LEVEL_DMPAC_OUT_0_DRU_ERROR_{n}_CLR (n=0..31) — Status ,write 1 to clear, for level_dmpac_out_0_en_dru_error_{n} (access R/W1TC)
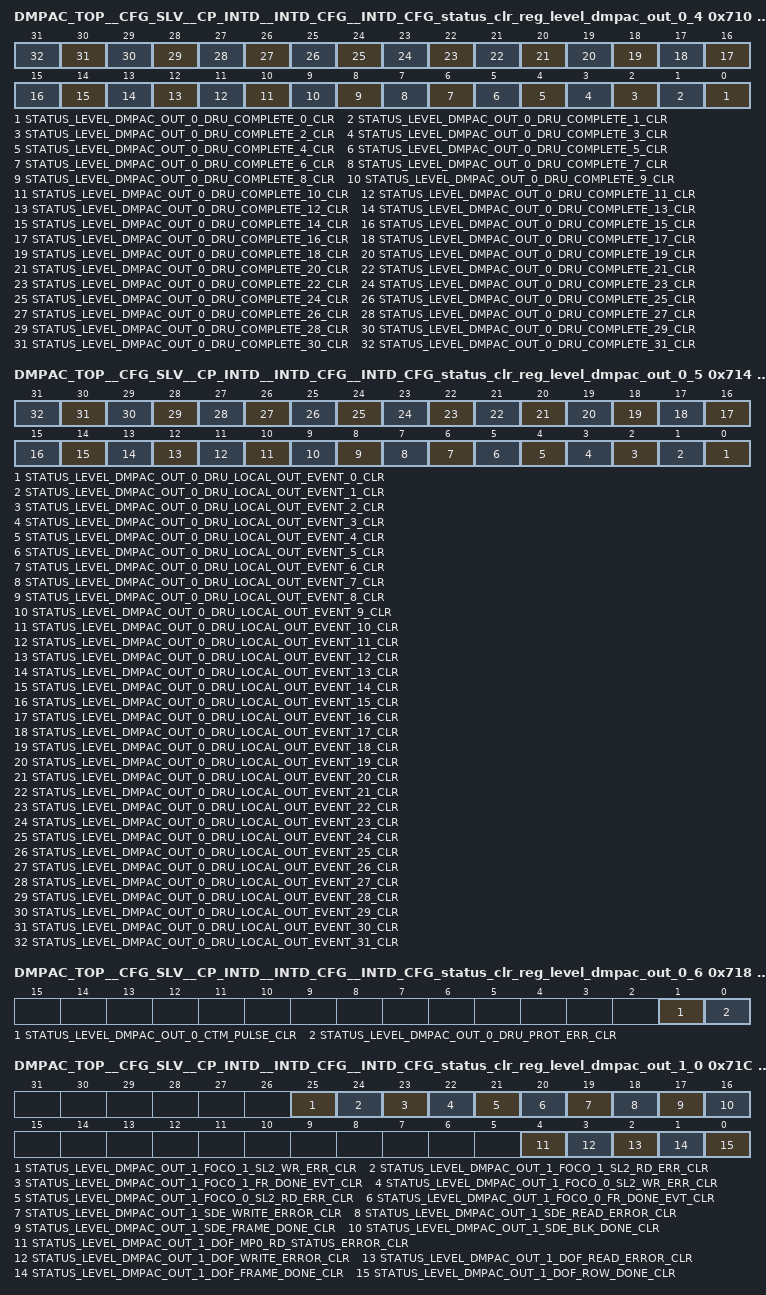
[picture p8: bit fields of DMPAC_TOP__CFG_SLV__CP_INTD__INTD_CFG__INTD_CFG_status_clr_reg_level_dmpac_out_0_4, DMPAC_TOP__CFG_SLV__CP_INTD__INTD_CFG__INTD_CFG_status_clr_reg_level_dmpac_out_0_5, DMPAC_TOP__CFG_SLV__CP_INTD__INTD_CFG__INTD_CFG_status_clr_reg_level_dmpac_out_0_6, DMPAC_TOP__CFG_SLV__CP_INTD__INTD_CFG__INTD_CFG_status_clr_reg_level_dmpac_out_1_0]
0x710 DMPAC_TOP__CFG_SLV__CP_INTD__INTD_CFG__INTD_CFG_status_clr_reg_level_dmpac_out_0_4 — Status Clear Register 4
  [n] STATUS_LEVEL_DMPAC_OUT_0_DRU_COMPLETE_{n}_CLR (n=0..31) — Status ,write 1 to clear, for level_dmpac_out_0_en_dru_complete_{n} (access R/W1TC)
0x714 DMPAC_TOP__CFG_SLV__CP_INTD__INTD_CFG__INTD_CFG_status_clr_reg_level_dmpac_out_0_5 — Status Clear Register 5
  [n] STATUS_LEVEL_DMPAC_OUT_0_DRU_LOCAL_OUT_EVENT_{n}_CLR (n=0..31) — Status ,write 1 to clear, for level_dmpac_out_0_en_dru_local_out_event_{n} (access R/W1TC)
0x718 DMPAC_TOP__CFG_SLV__CP_INTD__INTD_CFG__INTD_CFG_status_clr_reg_level_dmpac_out_0_6 — Status Clear Register 6
  [1] STATUS_LEVEL_DMPAC_OUT_0_CTM_PULSE_CLR — Status ,write 1 to clear, for level_dmpac_out_0_en_ctm_pulse (access R/W1TC)
  [0] STATUS_LEVEL_DMPAC_OUT_0_DRU_PROT_ERR_CLR — Status ,write 1 to clear, for level_dmpac_out_0_en_dru_prot_err (access R/W1TC)
0x71C DMPAC_TOP__CFG_SLV__CP_INTD__INTD_CFG__INTD_CFG_status_clr_reg_level_dmpac_out_1_0 — Status Clear Register 7
  [25] STATUS_LEVEL_DMPAC_OUT_1_FOCO_1_SL2_WR_ERR_CLR — Status ,write 1 to clear, for level_dmpac_out_1_en_foco_1_sl2_wr_err (access R/W1TC)
  [24] STATUS_LEVEL_DMPAC_OUT_1_FOCO_1_SL2_RD_ERR_CLR — Status ,write 1 to clear, for level_dmpac_out_1_en_foco_1_sl2_rd_err (access R/W1TC)
  [23] STATUS_LEVEL_DMPAC_OUT_1_FOCO_1_FR_DONE_EVT_CLR — Status ,write 1 to clear, for level_dmpac_out_1_en_foco_1_fr_done_evt (access R/W1TC)
  [22] STATUS_LEVEL_DMPAC_OUT_1_FOCO_0_SL2_WR_ERR_CLR — Status ,write 1 to clear, for level_dmpac_out_1_en_foco_0_sl2_wr_err (access R/W1TC)
  [21] STATUS_LEVEL_DMPAC_OUT_1_FOCO_0_SL2_RD_ERR_CLR — Status ,write 1 to clear, for level_dmpac_out_1_en_foco_0_sl2_rd_err (access R/W1TC)
  [20] STATUS_LEVEL_DMPAC_OUT_1_FOCO_0_FR_DONE_EVT_CLR — Status ,write 1 to clear, for level_dmpac_out_1_en_foco_0_fr_done_evt (access R/W1TC)
  [19] STATUS_LEVEL_DMPAC_OUT_1_SDE_WRITE_ERROR_CLR — Status ,write 1 to clear, for level_dmpac_out_1_en_sde_write_error (access R/W1TC)
  [18] STATUS_LEVEL_DMPAC_OUT_1_SDE_READ_ERROR_CLR — Status ,write 1 to clear, for level_dmpac_out_1_en_sde_read_error (access R/W1TC)
  [17] STATUS_LEVEL_DMPAC_OUT_1_SDE_FRAME_DONE_CLR — Status ,write 1 to clear, for level_dmpac_out_1_en_sde_frame_done (access R/W1TC)
  [16] STATUS_LEVEL_DMPAC_OUT_1_SDE_BLK_DONE_CLR — Status ,write 1 to clear, for level_dmpac_out_1_en_sde_blk_done (access R/W1TC)
  [4] STATUS_LEVEL_DMPAC_OUT_1_DOF_MP0_RD_STATUS_ERROR_CLR — Status ,write 1 to clear, for level_dmpac_out_1_en_dof_mp0_rd_status_error (access R/W1TC)
  [3] STATUS_LEVEL_DMPAC_OUT_1_DOF_WRITE_ERROR_CLR — Status ,write 1 to clear, for level_dmpac_out_1_en_dof_write_error (access R/W1TC)
  [2] STATUS_LEVEL_DMPAC_OUT_1_DOF_READ_ERROR_CLR — Status ,write 1 to clear, for level_dmpac_out_1_en_dof_read_error (access R/W1TC)
  [1] STATUS_LEVEL_DMPAC_OUT_1_DOF_FRAME_DONE_CLR — Status ,write 1 to clear, for level_dmpac_out_1_en_dof_frame_done (access R/W1TC)
  [0] STATUS_LEVEL_DMPAC_OUT_1_DOF_ROW_DONE_CLR — Status ,write 1 to clear, for level_dmpac_out_1_en_dof_row_done (access R/W1TC)
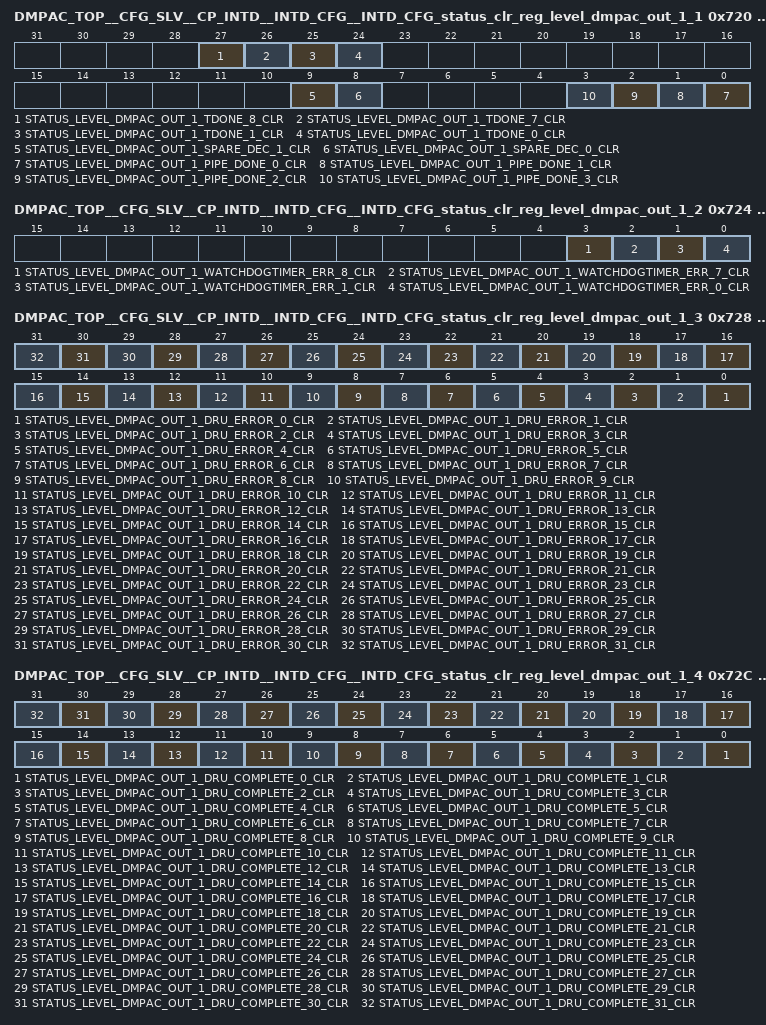
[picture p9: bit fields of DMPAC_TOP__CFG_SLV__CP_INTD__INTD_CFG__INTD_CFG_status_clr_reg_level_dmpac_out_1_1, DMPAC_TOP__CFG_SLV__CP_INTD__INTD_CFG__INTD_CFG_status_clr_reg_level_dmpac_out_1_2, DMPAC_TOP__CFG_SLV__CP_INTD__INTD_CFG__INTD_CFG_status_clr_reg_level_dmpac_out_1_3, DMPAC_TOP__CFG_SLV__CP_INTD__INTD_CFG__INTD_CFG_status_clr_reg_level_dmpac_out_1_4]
0x720 DMPAC_TOP__CFG_SLV__CP_INTD__INTD_CFG__INTD_CFG_status_clr_reg_level_dmpac_out_1_1 — Status Clear Register 8
  [27] STATUS_LEVEL_DMPAC_OUT_1_TDONE_8_CLR — Status ,write 1 to clear, for level_dmpac_out_1_en_tdone_8 (access R/W1TC)
  [26] STATUS_LEVEL_DMPAC_OUT_1_TDONE_7_CLR — Status ,write 1 to clear, for level_dmpac_out_1_en_tdone_7 (access R/W1TC)
  [25] STATUS_LEVEL_DMPAC_OUT_1_TDONE_1_CLR — Status ,write 1 to clear, for level_dmpac_out_1_en_tdone_1 (access R/W1TC)
  [24] STATUS_LEVEL_DMPAC_OUT_1_TDONE_0_CLR — Status ,write 1 to clear, for level_dmpac_out_1_en_tdone_0 (access R/W1TC)
  [9] STATUS_LEVEL_DMPAC_OUT_1_SPARE_DEC_1_CLR — Status ,write 1 to clear, for level_dmpac_out_1_en_spare_dec_1 (access R/W1TC)
  [8] STATUS_LEVEL_DMPAC_OUT_1_SPARE_DEC_0_CLR — Status ,write 1 to clear, for level_dmpac_out_1_en_spare_dec_0 (access R/W1TC)
  [n] STATUS_LEVEL_DMPAC_OUT_1_PIPE_DONE_{n}_CLR (n=0..3) — Status ,write 1 to clear, for level_dmpac_out_1_en_pipe_done_{n} (access R/W1TC)
0x724 DMPAC_TOP__CFG_SLV__CP_INTD__INTD_CFG__INTD_CFG_status_clr_reg_level_dmpac_out_1_2 — Status Clear Register 9
  [3] STATUS_LEVEL_DMPAC_OUT_1_WATCHDOGTIMER_ERR_8_CLR — Status ,write 1 to clear, for level_dmpac_out_1_en_watchdogtimer_err_8 (access R/W1TC)
  [2] STATUS_LEVEL_DMPAC_OUT_1_WATCHDOGTIMER_ERR_7_CLR — Status ,write 1 to clear, for level_dmpac_out_1_en_watchdogtimer_err_7 (access R/W1TC)
  [1] STATUS_LEVEL_DMPAC_OUT_1_WATCHDOGTIMER_ERR_1_CLR — Status ,write 1 to clear, for level_dmpac_out_1_en_watchdogtimer_err_1 (access R/W1TC)
  [0] STATUS_LEVEL_DMPAC_OUT_1_WATCHDOGTIMER_ERR_0_CLR — Status ,write 1 to clear, for level_dmpac_out_1_en_watchdogtimer_err_0 (access R/W1TC)
0x728 DMPAC_TOP__CFG_SLV__CP_INTD__INTD_CFG__INTD_CFG_status_clr_reg_level_dmpac_out_1_3 — Status Clear Register 10
  [n] STATUS_LEVEL_DMPAC_OUT_1_DRU_ERROR_{n}_CLR (n=0..31) — Status ,write 1 to clear, for level_dmpac_out_1_en_dru_error_{n} (access R/W1TC)
0x72C DMPAC_TOP__CFG_SLV__CP_INTD__INTD_CFG__INTD_CFG_status_clr_reg_level_dmpac_out_1_4 — Status Clear Register 11
  [n] STATUS_LEVEL_DMPAC_OUT_1_DRU_COMPLETE_{n}_CLR (n=0..31) — Status ,write 1 to clear, for level_dmpac_out_1_en_dru_complete_{n} (access R/W1TC)
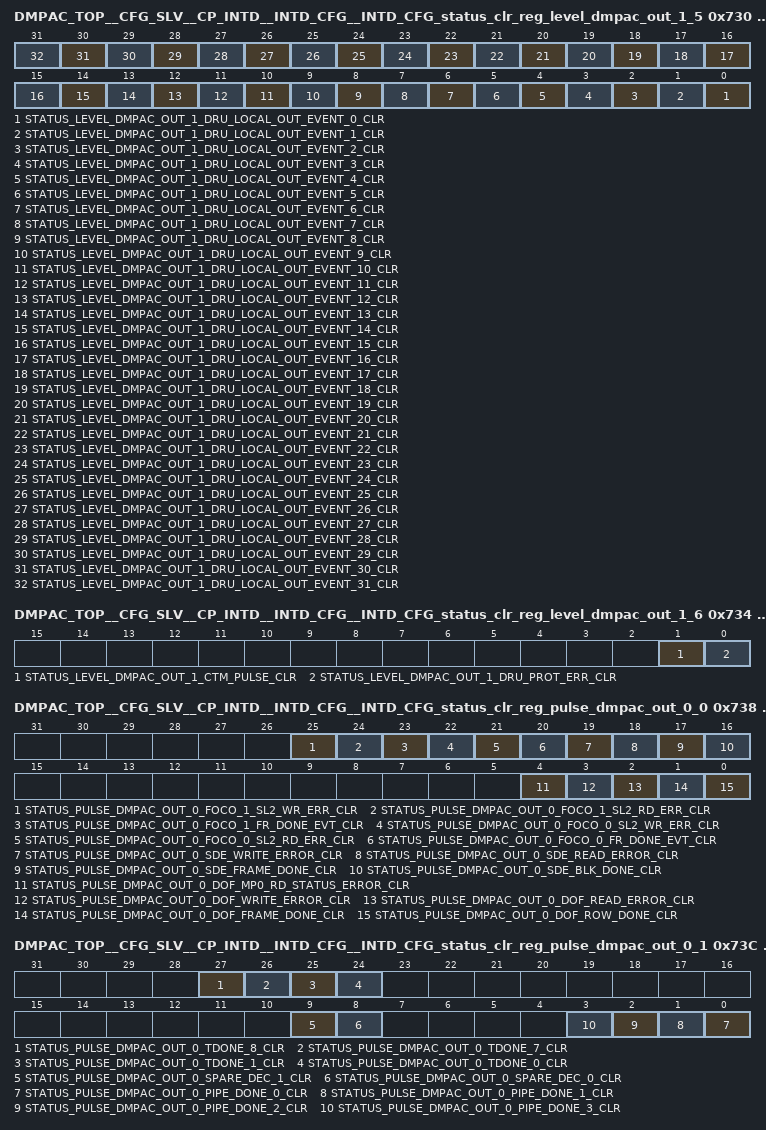
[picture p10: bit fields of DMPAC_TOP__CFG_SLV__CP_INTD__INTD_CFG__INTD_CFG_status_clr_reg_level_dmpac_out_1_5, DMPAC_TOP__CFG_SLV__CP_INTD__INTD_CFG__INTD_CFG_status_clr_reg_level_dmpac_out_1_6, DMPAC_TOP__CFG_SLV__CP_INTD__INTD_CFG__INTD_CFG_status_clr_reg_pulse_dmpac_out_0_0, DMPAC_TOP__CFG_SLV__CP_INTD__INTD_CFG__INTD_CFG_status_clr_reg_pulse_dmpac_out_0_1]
0x730 DMPAC_TOP__CFG_SLV__CP_INTD__INTD_CFG__INTD_CFG_status_clr_reg_level_dmpac_out_1_5 — Status Clear Register 12
  [n] STATUS_LEVEL_DMPAC_OUT_1_DRU_LOCAL_OUT_EVENT_{n}_CLR (n=0..31) — Status ,write 1 to clear, for level_dmpac_out_1_en_dru_local_out_event_{n} (access R/W1TC)
0x734 DMPAC_TOP__CFG_SLV__CP_INTD__INTD_CFG__INTD_CFG_status_clr_reg_level_dmpac_out_1_6 — Status Clear Register 13
  [1] STATUS_LEVEL_DMPAC_OUT_1_CTM_PULSE_CLR — Status ,write 1 to clear, for level_dmpac_out_1_en_ctm_pulse (access R/W1TC)
  [0] STATUS_LEVEL_DMPAC_OUT_1_DRU_PROT_ERR_CLR — Status ,write 1 to clear, for level_dmpac_out_1_en_dru_prot_err (access R/W1TC)
0x738 DMPAC_TOP__CFG_SLV__CP_INTD__INTD_CFG__INTD_CFG_status_clr_reg_pulse_dmpac_out_0_0 — Status Clear Register 14
  [25] STATUS_PULSE_DMPAC_OUT_0_FOCO_1_SL2_WR_ERR_CLR — Status ,write 1 to clear, for pulse_dmpac_out_0_en_foco_1_sl2_wr_err (access R/W1TC)
  [24] STATUS_PULSE_DMPAC_OUT_0_FOCO_1_SL2_RD_ERR_CLR — Status ,write 1 to clear, for pulse_dmpac_out_0_en_foco_1_sl2_rd_err (access R/W1TC)
  [23] STATUS_PULSE_DMPAC_OUT_0_FOCO_1_FR_DONE_EVT_CLR — Status ,write 1 to clear, for pulse_dmpac_out_0_en_foco_1_fr_done_evt (access R/W1TC)
  [22] STATUS_PULSE_DMPAC_OUT_0_FOCO_0_SL2_WR_ERR_CLR — Status ,write 1 to clear, for pulse_dmpac_out_0_en_foco_0_sl2_wr_err (access R/W1TC)
  [21] STATUS_PULSE_DMPAC_OUT_0_FOCO_0_SL2_RD_ERR_CLR — Status ,write 1 to clear, for pulse_dmpac_out_0_en_foco_0_sl2_rd_err (access R/W1TC)
  [20] STATUS_PULSE_DMPAC_OUT_0_FOCO_0_FR_DONE_EVT_CLR — Status ,write 1 to clear, for pulse_dmpac_out_0_en_foco_0_fr_done_evt (access R/W1TC)
  [19] STATUS_PULSE_DMPAC_OUT_0_SDE_WRITE_ERROR_CLR — Status ,write 1 to clear, for pulse_dmpac_out_0_en_sde_write_error (access R/W1TC)
  [18] STATUS_PULSE_DMPAC_OUT_0_SDE_READ_ERROR_CLR — Status ,write 1 to clear, for pulse_dmpac_out_0_en_sde_read_error (access R/W1TC)
  [17] STATUS_PULSE_DMPAC_OUT_0_SDE_FRAME_DONE_CLR — Status ,write 1 to clear, for pulse_dmpac_out_0_en_sde_frame_done (access R/W1TC)
  [16] STATUS_PULSE_DMPAC_OUT_0_SDE_BLK_DONE_CLR — Status ,write 1 to clear, for pulse_dmpac_out_0_en_sde_blk_done (access R/W1TC)
  [4] STATUS_PULSE_DMPAC_OUT_0_DOF_MP0_RD_STATUS_ERROR_CLR — Status ,write 1 to clear, for pulse_dmpac_out_0_en_dof_mp0_rd_status_error (access R/W1TC)
  [3] STATUS_PULSE_DMPAC_OUT_0_DOF_WRITE_ERROR_CLR — Status ,write 1 to clear, for pulse_dmpac_out_0_en_dof_write_error (access R/W1TC)
  [2] STATUS_PULSE_DMPAC_OUT_0_DOF_READ_ERROR_CLR — Status ,write 1 to clear, for pulse_dmpac_out_0_en_dof_read_error (access R/W1TC)
  [1] STATUS_PULSE_DMPAC_OUT_0_DOF_FRAME_DONE_CLR — Status ,write 1 to clear, for pulse_dmpac_out_0_en_dof_frame_done (access R/W1TC)
  [0] STATUS_PULSE_DMPAC_OUT_0_DOF_ROW_DONE_CLR — Status ,write 1 to clear, for pulse_dmpac_out_0_en_dof_row_done (access R/W1TC)
0x73C DMPAC_TOP__CFG_SLV__CP_INTD__INTD_CFG__INTD_CFG_status_clr_reg_pulse_dmpac_out_0_1 — Status Clear Register 15
  [27] STATUS_PULSE_DMPAC_OUT_0_TDONE_8_CLR — Status ,write 1 to clear, for pulse_dmpac_out_0_en_tdone_8 (access R/W1TC)
  [26] STATUS_PULSE_DMPAC_OUT_0_TDONE_7_CLR — Status ,write 1 to clear, for pulse_dmpac_out_0_en_tdone_7 (access R/W1TC)
  [25] STATUS_PULSE_DMPAC_OUT_0_TDONE_1_CLR — Status ,write 1 to clear, for pulse_dmpac_out_0_en_tdone_1 (access R/W1TC)
  [24] STATUS_PULSE_DMPAC_OUT_0_TDONE_0_CLR — Status ,write 1 to clear, for pulse_dmpac_out_0_en_tdone_0 (access R/W1TC)
  [9] STATUS_PULSE_DMPAC_OUT_0_SPARE_DEC_1_CLR — Status ,write 1 to clear, for pulse_dmpac_out_0_en_spare_dec_1 (access R/W1TC)
  [8] STATUS_PULSE_DMPAC_OUT_0_SPARE_DEC_0_CLR — Status ,write 1 to clear, for pulse_dmpac_out_0_en_spare_dec_0 (access R/W1TC)
  [n] STATUS_PULSE_DMPAC_OUT_0_PIPE_DONE_{n}_CLR (n=0..3) — Status ,write 1 to clear, for pulse_dmpac_out_0_en_pipe_done_{n} (access R/W1TC)
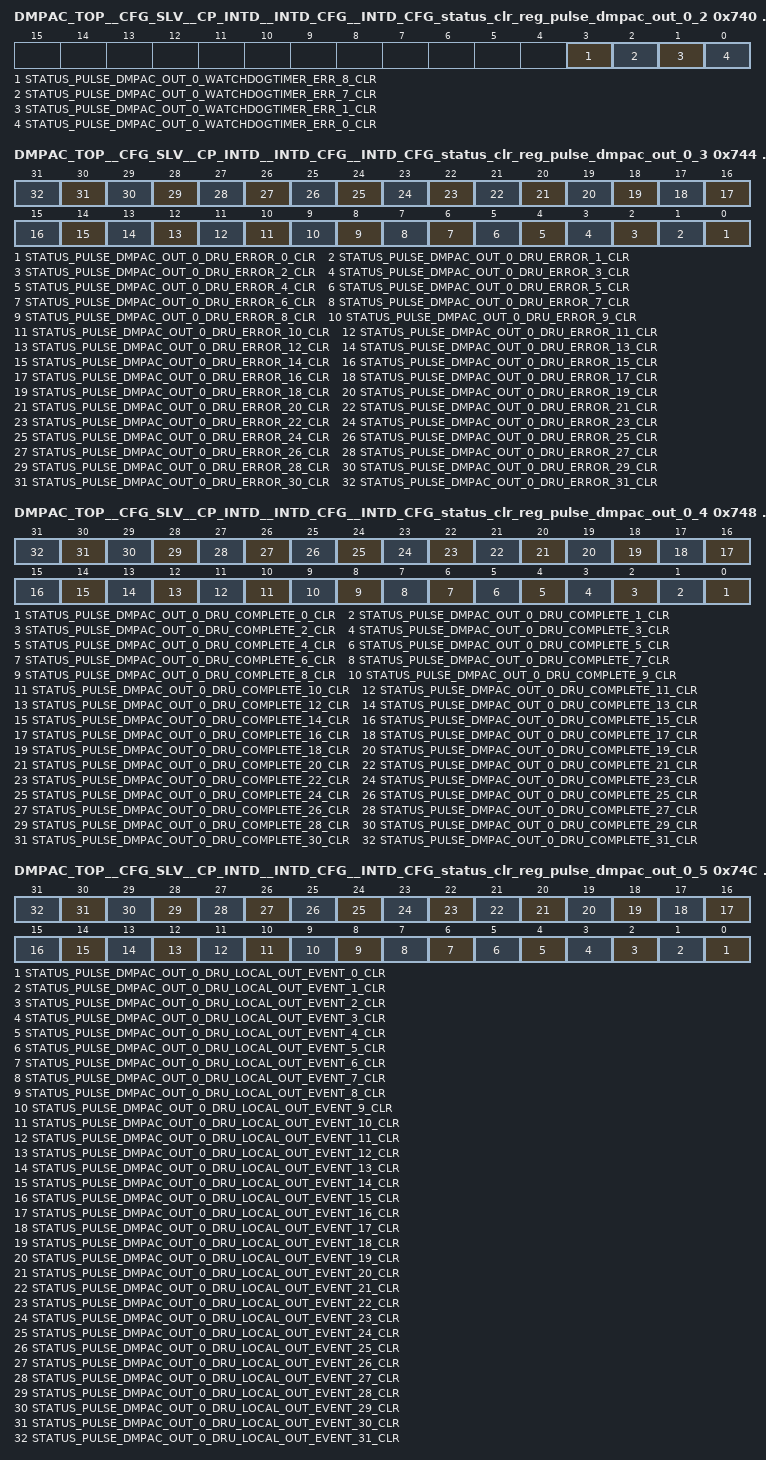
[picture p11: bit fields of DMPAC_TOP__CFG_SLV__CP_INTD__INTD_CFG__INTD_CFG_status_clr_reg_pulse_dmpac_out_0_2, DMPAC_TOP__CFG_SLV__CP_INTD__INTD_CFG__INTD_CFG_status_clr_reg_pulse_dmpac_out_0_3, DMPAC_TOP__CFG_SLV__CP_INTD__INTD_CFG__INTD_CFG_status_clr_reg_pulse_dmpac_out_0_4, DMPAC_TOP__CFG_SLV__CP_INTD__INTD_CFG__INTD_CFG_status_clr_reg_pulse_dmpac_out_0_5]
0x740 DMPAC_TOP__CFG_SLV__CP_INTD__INTD_CFG__INTD_CFG_status_clr_reg_pulse_dmpac_out_0_2 — Status Clear Register 16
  [3] STATUS_PULSE_DMPAC_OUT_0_WATCHDOGTIMER_ERR_8_CLR — Status ,write 1 to clear, for pulse_dmpac_out_0_en_watchdogtimer_err_8 (access R/W1TC)
  [2] STATUS_PULSE_DMPAC_OUT_0_WATCHDOGTIMER_ERR_7_CLR — Status ,write 1 to clear, for pulse_dmpac_out_0_en_watchdogtimer_err_7 (access R/W1TC)
  [1] STATUS_PULSE_DMPAC_OUT_0_WATCHDOGTIMER_ERR_1_CLR — Status ,write 1 to clear, for pulse_dmpac_out_0_en_watchdogtimer_err_1 (access R/W1TC)
  [0] STATUS_PULSE_DMPAC_OUT_0_WATCHDOGTIMER_ERR_0_CLR — Status ,write 1 to clear, for pulse_dmpac_out_0_en_watchdogtimer_err_0 (access R/W1TC)
0x744 DMPAC_TOP__CFG_SLV__CP_INTD__INTD_CFG__INTD_CFG_status_clr_reg_pulse_dmpac_out_0_3 — Status Clear Register 17
  [n] STATUS_PULSE_DMPAC_OUT_0_DRU_ERROR_{n}_CLR (n=0..31) — Status ,write 1 to clear, for pulse_dmpac_out_0_en_dru_error_{n} (access R/W1TC)
0x748 DMPAC_TOP__CFG_SLV__CP_INTD__INTD_CFG__INTD_CFG_status_clr_reg_pulse_dmpac_out_0_4 — Status Clear Register 18
  [n] STATUS_PULSE_DMPAC_OUT_0_DRU_COMPLETE_{n}_CLR (n=0..31) — Status ,write 1 to clear, for pulse_dmpac_out_0_en_dru_complete_{n} (access R/W1TC)
0x74C DMPAC_TOP__CFG_SLV__CP_INTD__INTD_CFG__INTD_CFG_status_clr_reg_pulse_dmpac_out_0_5 — Status Clear Register 19
  [n] STATUS_PULSE_DMPAC_OUT_0_DRU_LOCAL_OUT_EVENT_{n}_CLR (n=0..31) — Status ,write 1 to clear, for pulse_dmpac_out_0_en_dru_local_out_event_{n} (access R/W1TC)
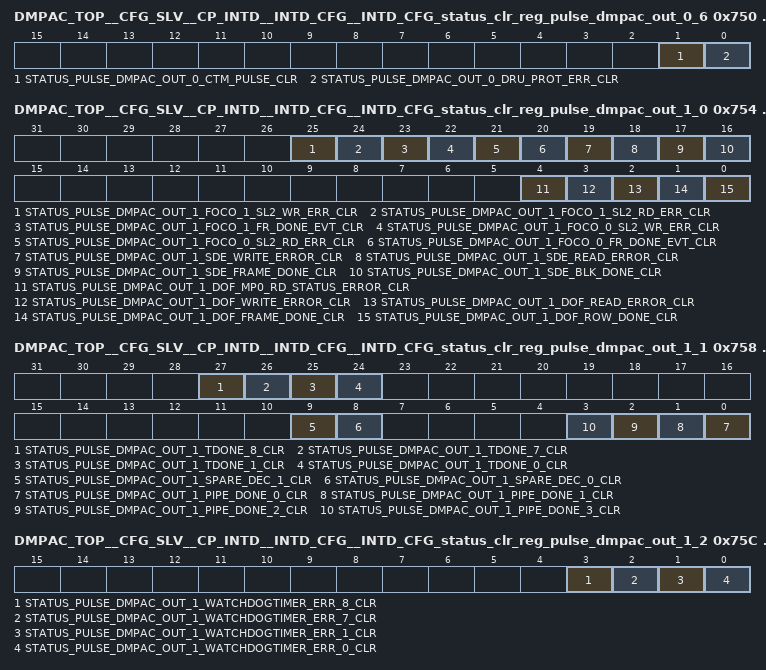
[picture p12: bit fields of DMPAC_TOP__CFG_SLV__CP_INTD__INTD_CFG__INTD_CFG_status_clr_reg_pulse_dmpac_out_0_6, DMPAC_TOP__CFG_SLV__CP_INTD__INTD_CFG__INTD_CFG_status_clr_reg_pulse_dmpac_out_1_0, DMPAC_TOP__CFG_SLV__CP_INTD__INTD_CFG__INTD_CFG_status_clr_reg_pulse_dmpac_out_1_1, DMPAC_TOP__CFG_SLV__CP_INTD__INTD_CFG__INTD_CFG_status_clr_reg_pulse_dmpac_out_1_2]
0x750 DMPAC_TOP__CFG_SLV__CP_INTD__INTD_CFG__INTD_CFG_status_clr_reg_pulse_dmpac_out_0_6 — Status Clear Register 20
  [1] STATUS_PULSE_DMPAC_OUT_0_CTM_PULSE_CLR — Status ,write 1 to clear, for pulse_dmpac_out_0_en_ctm_pulse (access R/W1TC)
  [0] STATUS_PULSE_DMPAC_OUT_0_DRU_PROT_ERR_CLR — Status ,write 1 to clear, for pulse_dmpac_out_0_en_dru_prot_err (access R/W1TC)
0x754 DMPAC_TOP__CFG_SLV__CP_INTD__INTD_CFG__INTD_CFG_status_clr_reg_pulse_dmpac_out_1_0 — Status Clear Register 21
  [25] STATUS_PULSE_DMPAC_OUT_1_FOCO_1_SL2_WR_ERR_CLR — Status ,write 1 to clear, for pulse_dmpac_out_1_en_foco_1_sl2_wr_err (access R/W1TC)
  [24] STATUS_PULSE_DMPAC_OUT_1_FOCO_1_SL2_RD_ERR_CLR — Status ,write 1 to clear, for pulse_dmpac_out_1_en_foco_1_sl2_rd_err (access R/W1TC)
  [23] STATUS_PULSE_DMPAC_OUT_1_FOCO_1_FR_DONE_EVT_CLR — Status ,write 1 to clear, for pulse_dmpac_out_1_en_foco_1_fr_done_evt (access R/W1TC)
  [22] STATUS_PULSE_DMPAC_OUT_1_FOCO_0_SL2_WR_ERR_CLR — Status ,write 1 to clear, for pulse_dmpac_out_1_en_foco_0_sl2_wr_err (access R/W1TC)
  [21] STATUS_PULSE_DMPAC_OUT_1_FOCO_0_SL2_RD_ERR_CLR — Status ,write 1 to clear, for pulse_dmpac_out_1_en_foco_0_sl2_rd_err (access R/W1TC)
  [20] STATUS_PULSE_DMPAC_OUT_1_FOCO_0_FR_DONE_EVT_CLR — Status ,write 1 to clear, for pulse_dmpac_out_1_en_foco_0_fr_done_evt (access R/W1TC)
  [19] STATUS_PULSE_DMPAC_OUT_1_SDE_WRITE_ERROR_CLR — Status ,write 1 to clear, for pulse_dmpac_out_1_en_sde_write_error (access R/W1TC)
  [18] STATUS_PULSE_DMPAC_OUT_1_SDE_READ_ERROR_CLR — Status ,write 1 to clear, for pulse_dmpac_out_1_en_sde_read_error (access R/W1TC)
  [17] STATUS_PULSE_DMPAC_OUT_1_SDE_FRAME_DONE_CLR — Status ,write 1 to clear, for pulse_dmpac_out_1_en_sde_frame_done (access R/W1TC)
  [16] STATUS_PULSE_DMPAC_OUT_1_SDE_BLK_DONE_CLR — Status ,write 1 to clear, for pulse_dmpac_out_1_en_sde_blk_done (access R/W1TC)
  [4] STATUS_PULSE_DMPAC_OUT_1_DOF_MP0_RD_STATUS_ERROR_CLR — Status ,write 1 to clear, for pulse_dmpac_out_1_en_dof_mp0_rd_status_error (access R/W1TC)
  [3] STATUS_PULSE_DMPAC_OUT_1_DOF_WRITE_ERROR_CLR — Status ,write 1 to clear, for pulse_dmpac_out_1_en_dof_write_error (access R/W1TC)
  [2] STATUS_PULSE_DMPAC_OUT_1_DOF_READ_ERROR_CLR — Status ,write 1 to clear, for pulse_dmpac_out_1_en_dof_read_error (access R/W1TC)
  [1] STATUS_PULSE_DMPAC_OUT_1_DOF_FRAME_DONE_CLR — Status ,write 1 to clear, for pulse_dmpac_out_1_en_dof_frame_done (access R/W1TC)
  [0] STATUS_PULSE_DMPAC_OUT_1_DOF_ROW_DONE_CLR — Status ,write 1 to clear, for pulse_dmpac_out_1_en_dof_row_done (access R/W1TC)
0x758 DMPAC_TOP__CFG_SLV__CP_INTD__INTD_CFG__INTD_CFG_status_clr_reg_pulse_dmpac_out_1_1 — Status Clear Register 22
  [27] STATUS_PULSE_DMPAC_OUT_1_TDONE_8_CLR — Status ,write 1 to clear, for pulse_dmpac_out_1_en_tdone_8 (access R/W1TC)
  [26] STATUS_PULSE_DMPAC_OUT_1_TDONE_7_CLR — Status ,write 1 to clear, for pulse_dmpac_out_1_en_tdone_7 (access R/W1TC)
  [25] STATUS_PULSE_DMPAC_OUT_1_TDONE_1_CLR — Status ,write 1 to clear, for pulse_dmpac_out_1_en_tdone_1 (access R/W1TC)
  [24] STATUS_PULSE_DMPAC_OUT_1_TDONE_0_CLR — Status ,write 1 to clear, for pulse_dmpac_out_1_en_tdone_0 (access R/W1TC)
  [9] STATUS_PULSE_DMPAC_OUT_1_SPARE_DEC_1_CLR — Status ,write 1 to clear, for pulse_dmpac_out_1_en_spare_dec_1 (access R/W1TC)
  [8] STATUS_PULSE_DMPAC_OUT_1_SPARE_DEC_0_CLR — Status ,write 1 to clear, for pulse_dmpac_out_1_en_spare_dec_0 (access R/W1TC)
  [n] STATUS_PULSE_DMPAC_OUT_1_PIPE_DONE_{n}_CLR (n=0..3) — Status ,write 1 to clear, for pulse_dmpac_out_1_en_pipe_done_{n} (access R/W1TC)
0x75C DMPAC_TOP__CFG_SLV__CP_INTD__INTD_CFG__INTD_CFG_status_clr_reg_pulse_dmpac_out_1_2 — Status Clear Register 23
  [3] STATUS_PULSE_DMPAC_OUT_1_WATCHDOGTIMER_ERR_8_CLR — Status ,write 1 to clear, for pulse_dmpac_out_1_en_watchdogtimer_err_8 (access R/W1TC)
  [2] STATUS_PULSE_DMPAC_OUT_1_WATCHDOGTIMER_ERR_7_CLR — Status ,write 1 to clear, for pulse_dmpac_out_1_en_watchdogtimer_err_7 (access R/W1TC)
  [1] STATUS_PULSE_DMPAC_OUT_1_WATCHDOGTIMER_ERR_1_CLR — Status ,write 1 to clear, for pulse_dmpac_out_1_en_watchdogtimer_err_1 (access R/W1TC)
  [0] STATUS_PULSE_DMPAC_OUT_1_WATCHDOGTIMER_ERR_0_CLR — Status ,write 1 to clear, for pulse_dmpac_out_1_en_watchdogtimer_err_0 (access R/W1TC)
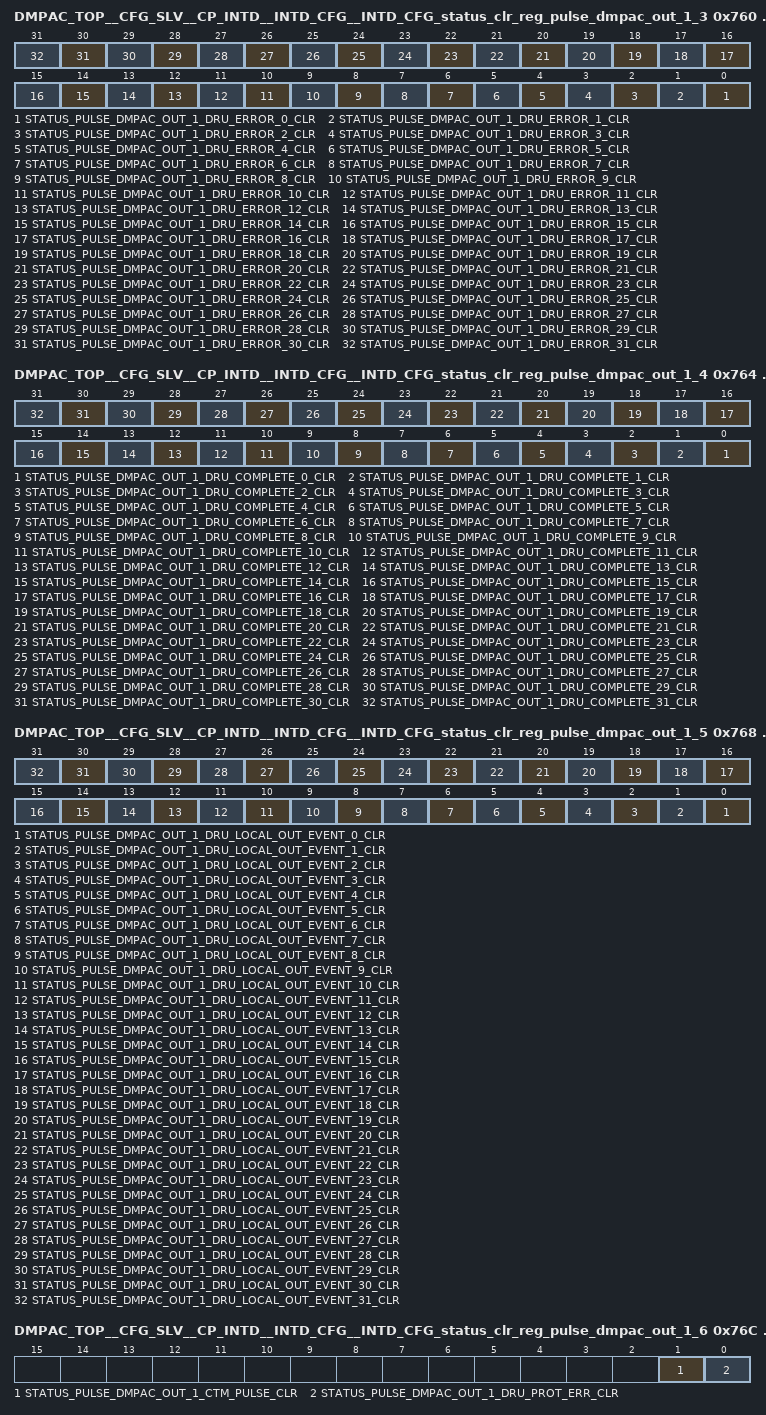
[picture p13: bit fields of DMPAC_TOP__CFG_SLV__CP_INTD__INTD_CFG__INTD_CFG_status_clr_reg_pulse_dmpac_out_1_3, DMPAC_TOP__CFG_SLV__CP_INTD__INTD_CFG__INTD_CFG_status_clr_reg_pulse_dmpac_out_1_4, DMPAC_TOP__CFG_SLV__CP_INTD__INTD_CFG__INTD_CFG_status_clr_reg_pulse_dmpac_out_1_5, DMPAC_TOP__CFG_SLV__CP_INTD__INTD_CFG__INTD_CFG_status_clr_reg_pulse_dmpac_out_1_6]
0x760 DMPAC_TOP__CFG_SLV__CP_INTD__INTD_CFG__INTD_CFG_status_clr_reg_pulse_dmpac_out_1_3 — Status Clear Register 24
  [n] STATUS_PULSE_DMPAC_OUT_1_DRU_ERROR_{n}_CLR (n=0..31) — Status ,write 1 to clear, for pulse_dmpac_out_1_en_dru_error_{n} (access R/W1TC)
0x764 DMPAC_TOP__CFG_SLV__CP_INTD__INTD_CFG__INTD_CFG_status_clr_reg_pulse_dmpac_out_1_4 — Status Clear Register 25
  [n] STATUS_PULSE_DMPAC_OUT_1_DRU_COMPLETE_{n}_CLR (n=0..31) — Status ,write 1 to clear, for pulse_dmpac_out_1_en_dru_complete_{n} (access R/W1TC)
0x768 DMPAC_TOP__CFG_SLV__CP_INTD__INTD_CFG__INTD_CFG_status_clr_reg_pulse_dmpac_out_1_5 — Status Clear Register 26
  [n] STATUS_PULSE_DMPAC_OUT_1_DRU_LOCAL_OUT_EVENT_{n}_CLR (n=0..31) — Status ,write 1 to clear, for pulse_dmpac_out_1_en_dru_local_out_event_{n} (access R/W1TC)
0x76C DMPAC_TOP__CFG_SLV__CP_INTD__INTD_CFG__INTD_CFG_status_clr_reg_pulse_dmpac_out_1_6 — Status Clear Register 27
  [1] STATUS_PULSE_DMPAC_OUT_1_CTM_PULSE_CLR — Status ,write 1 to clear, for pulse_dmpac_out_1_en_ctm_pulse (access R/W1TC)
  [0] STATUS_PULSE_DMPAC_OUT_1_DRU_PROT_ERR_CLR — Status ,write 1 to clear, for pulse_dmpac_out_1_en_dru_prot_err (access R/W1TC)
0xA80 DMPAC_TOP__CFG_SLV__CP_INTD__INTD_CFG__INTD_CFG_intr_vector_reg_level_dmpac_out_0 ro — Interrupt Vector for level_dmpac_out_0
  [31:0] INTR_VECTOR_LEVEL_DMPAC_OUT_0 — Interrupt Vector
0xA84 DMPAC_TOP__CFG_SLV__CP_INTD__INTD_CFG__INTD_CFG_intr_vector_reg_level_dmpac_out_1 ro — Interrupt Vector for level_dmpac_out_1
  [31:0] INTR_VECTOR_LEVEL_DMPAC_OUT_1 — Interrupt Vector
0xA88 DMPAC_TOP__CFG_SLV__CP_INTD__INTD_CFG__INTD_CFG_intr_vector_reg_pulse_dmpac_out_0 ro — Interrupt Vector for pulse_dmpac_out_0
  [31:0] INTR_VECTOR_PULSE_DMPAC_OUT_0 — Interrupt Vector
0xA8C DMPAC_TOP__CFG_SLV__CP_INTD__INTD_CFG__INTD_CFG_intr_vector_reg_pulse_dmpac_out_1 ro — Interrupt Vector for pulse_dmpac_out_1
  [31:0] INTR_VECTOR_PULSE_DMPAC_OUT_1 — Interrupt Vector
